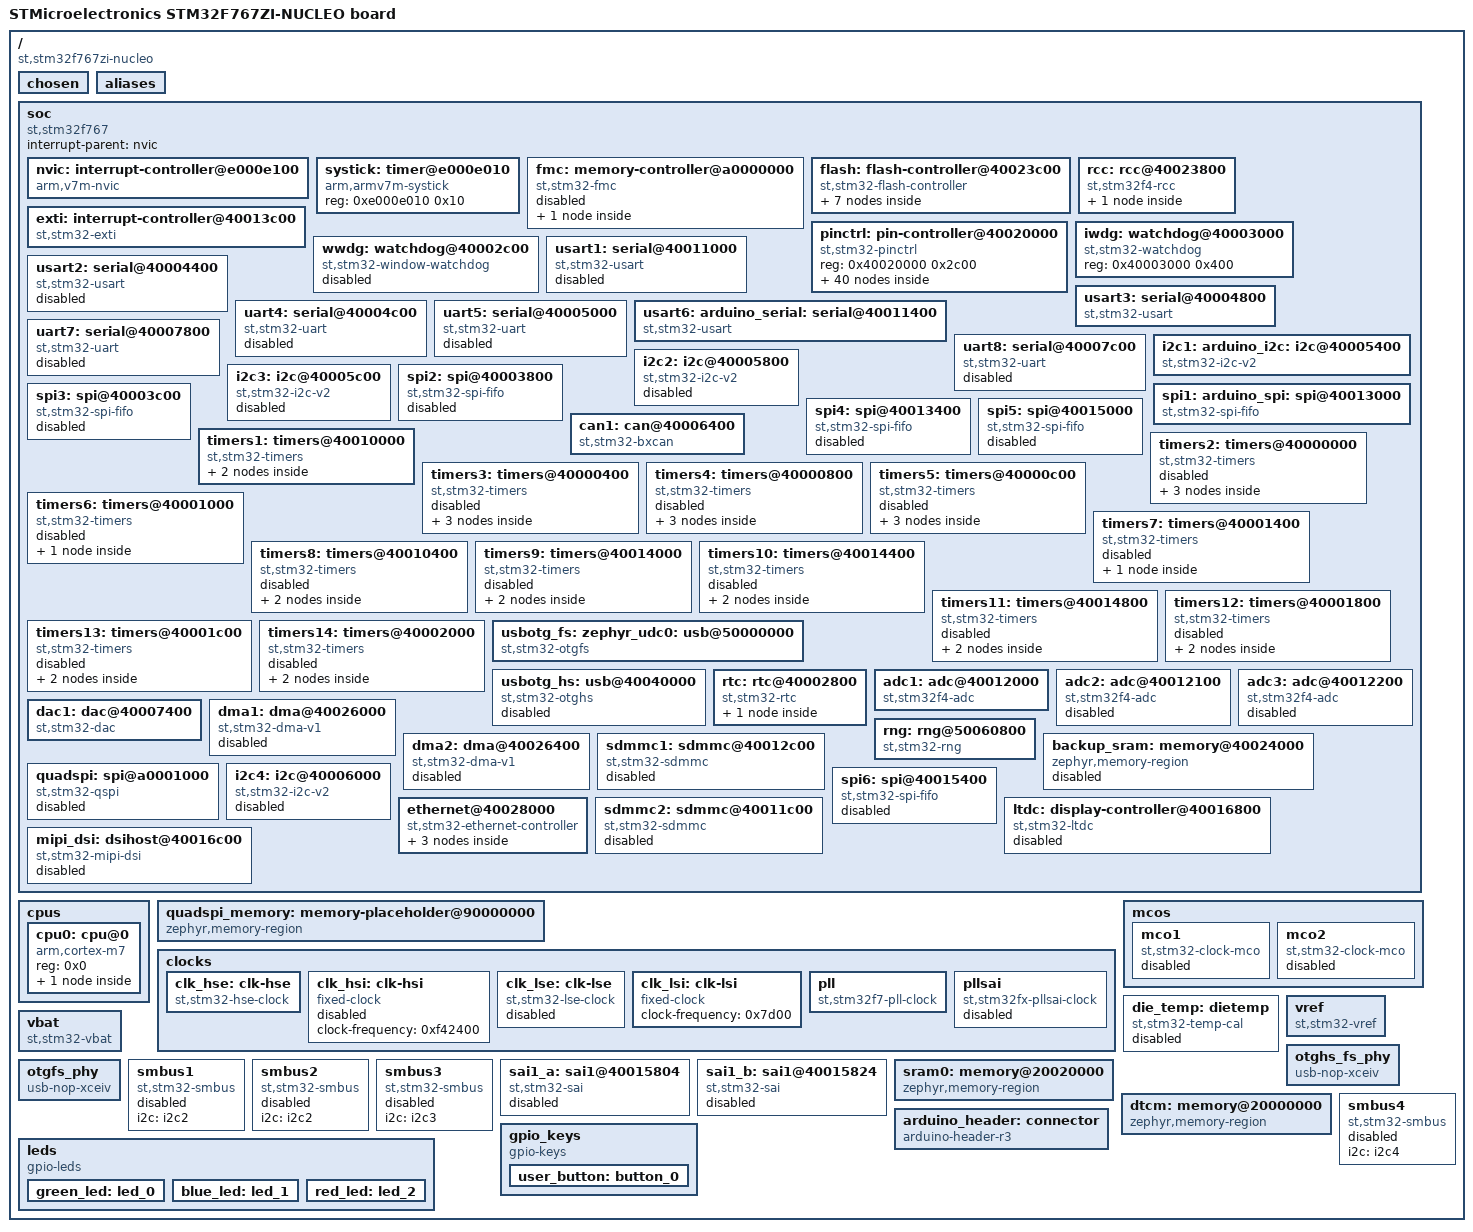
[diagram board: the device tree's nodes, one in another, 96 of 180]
/dts-v1/;

/* node '/' defined in zephyr/dts/common/skeleton.dtsi:9 */
/ {
	#address-cells = < 0x1 >;                              /* in zephyr/dts/common/skeleton.dtsi:10 */
	#size-cells = < 0x1 >;                                 /* in zephyr/dts/common/skeleton.dtsi:11 */
	model = "STMicroelectronics STM32F767ZI-NUCLEO board"; /* in zephyr/boards/st/nucleo_f767zi/nucleo_f767zi.dts:21 */
	compatible = "st,stm32f767zi-nucleo";                  /* in zephyr/boards/st/nucleo_f767zi/nucleo_f767zi.dts:22 */

	/* node '/chosen' defined in zephyr/dts/common/skeleton.dtsi:13 */
	chosen {
		zephyr,entropy = &rng;                    /* in zephyr/dts/arm/st/f7/stm32f7.dtsi:29 */
		zephyr,flash-controller = &flash;         /* in zephyr/dts/arm/st/f7/stm32f7.dtsi:30 */
		zephyr,console = &usart3;                 /* in zephyr/boards/st/nucleo_f767zi/nucleo_f767zi.dts:25 */
		zephyr,shell-uart = &usart3;              /* in zephyr/boards/st/nucleo_f767zi/nucleo_f767zi.dts:26 */
		zephyr,sram = &sram0;                     /* in zephyr/boards/st/nucleo_f767zi/nucleo_f767zi.dts:27 */
		zephyr,flash = &flash0;                   /* in zephyr/boards/st/nucleo_f767zi/nucleo_f767zi.dts:28 */
		zephyr,code-partition = &slot0_partition; /* in zephyr/boards/st/nucleo_f767zi/nucleo_f767zi.dts:29 */
		zephyr,dtcm = &dtcm;                      /* in zephyr/boards/st/nucleo_f767zi/nucleo_f767zi.dts:30 */
		zephyr,canbus = &can1;                    /* in zephyr/boards/st/nucleo_f767zi/nucleo_f767zi.dts:31 */
	};

	/* node '/aliases' defined in zephyr/dts/common/skeleton.dtsi:15 */
	aliases {
		led0 = &green_led;    /* in zephyr/boards/st/nucleo_f767zi/nucleo_f767zi.dts:64 */
		led1 = &blue_led;     /* in zephyr/boards/st/nucleo_f767zi/nucleo_f767zi.dts:65 */
		led2 = &red_led;      /* in zephyr/boards/st/nucleo_f767zi/nucleo_f767zi.dts:66 */
		sw0 = &user_button;   /* in zephyr/boards/st/nucleo_f767zi/nucleo_f767zi.dts:67 */
		watchdog0 = &iwdg;    /* in zephyr/boards/st/nucleo_f767zi/nucleo_f767zi.dts:68 */
		volt-sensor0 = &vref; /* in zephyr/boards/st/nucleo_f767zi/nucleo_f767zi.dts:69 */
		volt-sensor1 = &vbat; /* in zephyr/boards/st/nucleo_f767zi/nucleo_f767zi.dts:70 */
	};

	/* node '/soc' defined in zephyr/dts/arm/armv7-m.dtsi:6 */
	soc {
		#address-cells = < 0x1 >;     /* in zephyr/dts/arm/armv7-m.dtsi:7 */
		#size-cells = < 0x1 >;        /* in zephyr/dts/arm/armv7-m.dtsi:8 */
		interrupt-parent = < &nvic >; /* in zephyr/dts/arm/armv7-m.dtsi:10 */
		ranges;                       /* in zephyr/dts/arm/armv7-m.dtsi:11 */
		compatible = "st,stm32f767",
		             "st,stm32f7",
		             "simple-bus";    /* in zephyr/dts/arm/st/f7/stm32f767.dtsi:13 */

		/* node '/soc/interrupt-controller@e000e100' defined in zephyr/dts/arm/armv7-m.dtsi:13 */
		nvic: interrupt-controller@e000e100 {
			#address-cells = < 0x1 >;            /* in zephyr/dts/arm/armv7-m.dtsi:14 */
			compatible = "arm,v7m-nvic";         /* in zephyr/dts/arm/armv7-m.dtsi:15 */
			reg = < 0xe000e100 0xc00 >;          /* in zephyr/dts/arm/armv7-m.dtsi:16 */
			interrupt-controller;                /* in zephyr/dts/arm/armv7-m.dtsi:17 */
			#interrupt-cells = < 0x2 >;          /* in zephyr/dts/arm/armv7-m.dtsi:18 */
			arm,num-irq-priority-bits = < 0x4 >; /* in zephyr/dts/arm/st/f7/stm32f7.dtsi:1018 */
			phandle = < 0x1 >;                   /* in zephyr/dts/arm/armv7-m.dtsi:10 */
		};

		/* node '/soc/timer@e000e010' defined in zephyr/dts/arm/armv7-m.dtsi:21 */
		systick: timer@e000e010 {
			compatible = "arm,armv7m-systick"; /* in zephyr/dts/arm/armv7-m.dtsi:22 */
			reg = < 0xe000e010 0x10 >;         /* in zephyr/dts/arm/armv7-m.dtsi:23 */
		};

		/* node '/soc/memory-controller@a0000000' defined in zephyr/dts/arm/st/f7/stm32f7.dtsi:113 */
		fmc: memory-controller@a0000000 {
			compatible = "st,stm32-fmc"; /* in zephyr/dts/arm/st/f7/stm32f7.dtsi:114 */
			reg = < 0xa0000000 0x400 >;  /* in zephyr/dts/arm/st/f7/stm32f7.dtsi:115 */
			clocks = < &rcc 0x38 0x1 >;  /* in zephyr/dts/arm/st/f7/stm32f7.dtsi:116 */
			status = "disabled";         /* in zephyr/dts/arm/st/f7/stm32f7.dtsi:117 */

			/* node '/soc/memory-controller@a0000000/sdram' defined in zephyr/dts/arm/st/f7/stm32f7.dtsi:119 */
			sdram: sdram {
				compatible = "st,stm32-fmc-sdram"; /* in zephyr/dts/arm/st/f7/stm32f7.dtsi:120 */
				#address-cells = < 0x1 >;          /* in zephyr/dts/arm/st/f7/stm32f7.dtsi:121 */
				#size-cells = < 0x0 >;             /* in zephyr/dts/arm/st/f7/stm32f7.dtsi:122 */
				status = "disabled";               /* in zephyr/dts/arm/st/f7/stm32f7.dtsi:123 */
			};
		};

		/* node '/soc/flash-controller@40023c00' defined in zephyr/dts/arm/st/f7/stm32f7.dtsi:127 */
		flash: flash-controller@40023c00 {
			compatible = "st,stm32-flash-controller",
			             "st,stm32f7-flash-controller"; /* in zephyr/dts/arm/st/f7/stm32f7.dtsi:128 */
			reg = < 0x40023c00 0x400 >;                 /* in zephyr/dts/arm/st/f7/stm32f7.dtsi:129 */
			interrupts = < 0x4 0x0 >;                   /* in zephyr/dts/arm/st/f7/stm32f7.dtsi:130 */
			#address-cells = < 0x1 >;                   /* in zephyr/dts/arm/st/f7/stm32f7.dtsi:132 */
			#size-cells = < 0x1 >;                      /* in zephyr/dts/arm/st/f7/stm32f7.dtsi:133 */

			/* node '/soc/flash-controller@40023c00/flash@8000000' defined in zephyr/dts/arm/st/f7/stm32f7.dtsi:135 */
			flash0: flash@8000000 {
				compatible = "st,stm32-nv-flash",
				             "soc-nv-flash";      /* in zephyr/dts/arm/st/f7/stm32f7.dtsi:136 */
				write-block-size = < 0x1 >;       /* in zephyr/dts/arm/st/f7/stm32f7.dtsi:138 */
				max-erase-time = < 0xfa0 >;       /* in zephyr/dts/arm/st/f7/stm32f7.dtsi:140 */
				reg = < 0x8000000 0x200000 >;     /* in zephyr/dts/arm/st/f7/stm32f767Xi.dtsi:13 */

				/* node '/soc/flash-controller@40023c00/flash@8000000/partitions' defined in zephyr/boards/st/nucleo_f767zi/nucleo_f767zi.dts:219 */
				partitions {
					compatible = "fixed-partitions"; /* in zephyr/boards/st/nucleo_f767zi/nucleo_f767zi.dts:220 */
					#address-cells = < 0x1 >;        /* in zephyr/boards/st/nucleo_f767zi/nucleo_f767zi.dts:221 */
					#size-cells = < 0x1 >;           /* in zephyr/boards/st/nucleo_f767zi/nucleo_f767zi.dts:222 */

					/* node '/soc/flash-controller@40023c00/flash@8000000/partitions/partition@0' defined in zephyr/boards/st/nucleo_f767zi/nucleo_f767zi.dts:228 */
					boot_partition: partition@0 {
						label = "mcuboot";     /* in zephyr/boards/st/nucleo_f767zi/nucleo_f767zi.dts:229 */
						reg = < 0x0 0x10000 >; /* in zephyr/boards/st/nucleo_f767zi/nucleo_f767zi.dts:230 */
						read-only;             /* in zephyr/boards/st/nucleo_f767zi/nucleo_f767zi.dts:231 */
					};

					/* node '/soc/flash-controller@40023c00/flash@8000000/partitions/partition@10000' defined in zephyr/boards/st/nucleo_f767zi/nucleo_f767zi.dts:239 */
					storage_partition: partition@10000 {
						label = "storage";         /* in zephyr/boards/st/nucleo_f767zi/nucleo_f767zi.dts:240 */
						reg = < 0x10000 0x10000 >; /* in zephyr/boards/st/nucleo_f767zi/nucleo_f767zi.dts:241 */
					};

					/* node '/soc/flash-controller@40023c00/flash@8000000/partitions/partition@40000' defined in zephyr/boards/st/nucleo_f767zi/nucleo_f767zi.dts:251 */
					slot0_partition: partition@40000 {
						label = "image-0";         /* in zephyr/boards/st/nucleo_f767zi/nucleo_f767zi.dts:252 */
						reg = < 0x40000 0xc0000 >; /* in zephyr/boards/st/nucleo_f767zi/nucleo_f767zi.dts:253 */
					};

					/* node '/soc/flash-controller@40023c00/flash@8000000/partitions/partition@100000' defined in zephyr/boards/st/nucleo_f767zi/nucleo_f767zi.dts:259 */
					slot1_partition: partition@100000 {
						label = "image-1";          /* in zephyr/boards/st/nucleo_f767zi/nucleo_f767zi.dts:260 */
						reg = < 0x100000 0xc0000 >; /* in zephyr/boards/st/nucleo_f767zi/nucleo_f767zi.dts:261 */
					};

					/* node '/soc/flash-controller@40023c00/flash@8000000/partitions/partition@1C0000' defined in zephyr/boards/st/nucleo_f767zi/nucleo_f767zi.dts:267 */
					scratch_partition: partition@1C0000 {
						label = "image-scratch";    /* in zephyr/boards/st/nucleo_f767zi/nucleo_f767zi.dts:268 */
						reg = < 0x1c0000 0x40000 >; /* in zephyr/boards/st/nucleo_f767zi/nucleo_f767zi.dts:269 */
					};
				};
			};
		};

		/* node '/soc/rcc@40023800' defined in zephyr/dts/arm/st/f7/stm32f7.dtsi:144 */
		rcc: rcc@40023800 {
			compatible = "st,stm32f4-rcc";   /* in zephyr/dts/arm/st/f7/stm32f7.dtsi:145 */
			#clock-cells = < 0x2 >;          /* in zephyr/dts/arm/st/f7/stm32f7.dtsi:146 */
			reg = < 0x40023800 0x400 >;      /* in zephyr/dts/arm/st/f7/stm32f7.dtsi:147 */
			clocks = < &pll >;               /* in zephyr/boards/st/nucleo_f767zi/nucleo_f767zi.dts:94 */
			clock-frequency = < 0xcdfe600 >; /* in zephyr/boards/st/nucleo_f767zi/nucleo_f767zi.dts:95 */
			ahb-prescaler = < 0x1 >;         /* in zephyr/boards/st/nucleo_f767zi/nucleo_f767zi.dts:96 */
			apb1-prescaler = < 0x4 >;        /* in zephyr/boards/st/nucleo_f767zi/nucleo_f767zi.dts:97 */
			apb2-prescaler = < 0x2 >;        /* in zephyr/boards/st/nucleo_f767zi/nucleo_f767zi.dts:98 */
			phandle = < 0x2 >;               /* in zephyr/dts/arm/st/f7/stm32f7.dtsi:116 */

			/* node '/soc/rcc@40023800/reset-controller' defined in zephyr/dts/arm/st/f7/stm32f7.dtsi:149 */
			rctl: reset-controller {
				compatible = "st,stm32-rcc-rctl"; /* in zephyr/dts/arm/st/f7/stm32f7.dtsi:150 */
				#reset-cells = < 0x1 >;           /* in zephyr/dts/arm/st/f7/stm32f7.dtsi:151 */
				phandle = < 0x4 >;                /* in zephyr/dts/arm/st/f7/stm32f7.dtsi:268 */
			};
		};

		/* node '/soc/interrupt-controller@40013c00' defined in zephyr/dts/arm/st/f7/stm32f7.dtsi:155 */
		exti: interrupt-controller@40013c00 {
			compatible = "st,stm32-exti";  /* in zephyr/dts/arm/st/f7/stm32f7.dtsi:156 */
			interrupt-controller;          /* in zephyr/dts/arm/st/f7/stm32f7.dtsi:157 */
			#interrupt-cells = < 0x1 >;    /* in zephyr/dts/arm/st/f7/stm32f7.dtsi:158 */
			#address-cells = < 0x0 >;      /* in zephyr/dts/arm/st/f7/stm32f7.dtsi:159 */
			reg = < 0x40013c00 0x400 >;    /* in zephyr/dts/arm/st/f7/stm32f7.dtsi:160 */
			clocks = < &rcc 0x44 0x4000 >; /* in zephyr/dts/arm/st/f7/stm32f7.dtsi:161 */
			num-lines = < 0x20 >;          /* in zephyr/dts/arm/st/f7/stm32f7.dtsi:162 */
			interrupts = < 0x6 0x0 >,
			             < 0x7 0x0 >,
			             < 0x8 0x0 >,
			             < 0x9 0x0 >,
			             < 0xa 0x0 >,
			             < 0x17 0x0 >,
			             < 0x28 0x0 >;     /* in zephyr/dts/arm/st/f7/stm32f7.dtsi:163 */
			interrupt-names = "line0",
			                  "line1",
			                  "line2",
			                  "line3",
			                  "line4",
			                  "line5-9",
			                  "line10-15"; /* in zephyr/dts/arm/st/f7/stm32f7.dtsi:165 */
			line-ranges = < 0x0 0x1 >,
			              < 0x1 0x1 >,
			              < 0x2 0x1 >,
			              < 0x3 0x1 >,
			              < 0x4 0x1 >,
			              < 0x5 0x5 >,
			              < 0xa 0x6 >;     /* in zephyr/dts/arm/st/f7/stm32f7.dtsi:167 */
		};

		/* node '/soc/pin-controller@40020000' defined in zephyr/dts/arm/st/f7/stm32f7.dtsi:171 */
		pinctrl: pin-controller@40020000 {
			compatible = "st,stm32-pinctrl"; /* in zephyr/dts/arm/st/f7/stm32f7.dtsi:172 */
			#address-cells = < 0x1 >;        /* in zephyr/dts/arm/st/f7/stm32f7.dtsi:173 */
			#size-cells = < 0x1 >;           /* in zephyr/dts/arm/st/f7/stm32f7.dtsi:174 */
			reg = < 0x40020000 0x2c00 >;     /* in zephyr/dts/arm/st/f7/stm32f765.dtsi:30 */

			/* node '/soc/pin-controller@40020000/gpio@40020000' defined in zephyr/dts/arm/st/f7/stm32f7.dtsi:177 */
			gpioa: gpio@40020000 {
				compatible = "st,stm32-gpio"; /* in zephyr/dts/arm/st/f7/stm32f7.dtsi:178 */
				gpio-controller;              /* in zephyr/dts/arm/st/f7/stm32f7.dtsi:179 */
				#gpio-cells = < 0x2 >;        /* in zephyr/dts/arm/st/f7/stm32f7.dtsi:180 */
				reg = < 0x40020000 0x400 >;   /* in zephyr/dts/arm/st/f7/stm32f7.dtsi:181 */
				clocks = < &rcc 0x30 0x1 >;   /* in zephyr/dts/arm/st/f7/stm32f7.dtsi:182 */
				phandle = < 0x2c >;           /* in zephyr/boards/st/nucleo_f767zi/arduino_r3_connector.dtsi:15 */
			};

			/* node '/soc/pin-controller@40020000/gpio@40020400' defined in zephyr/dts/arm/st/f7/stm32f7.dtsi:185 */
			gpiob: gpio@40020400 {
				compatible = "st,stm32-gpio"; /* in zephyr/dts/arm/st/f7/stm32f7.dtsi:186 */
				gpio-controller;              /* in zephyr/dts/arm/st/f7/stm32f7.dtsi:187 */
				#gpio-cells = < 0x2 >;        /* in zephyr/dts/arm/st/f7/stm32f7.dtsi:188 */
				reg = < 0x40020400 0x400 >;   /* in zephyr/dts/arm/st/f7/stm32f7.dtsi:189 */
				clocks = < &rcc 0x30 0x2 >;   /* in zephyr/dts/arm/st/f7/stm32f7.dtsi:190 */
				phandle = < 0x31 >;           /* in zephyr/boards/st/nucleo_f767zi/arduino_r3_connector.dtsi:15 */
			};

			/* node '/soc/pin-controller@40020000/gpio@40020800' defined in zephyr/dts/arm/st/f7/stm32f7.dtsi:193 */
			gpioc: gpio@40020800 {
				compatible = "st,stm32-gpio"; /* in zephyr/dts/arm/st/f7/stm32f7.dtsi:194 */
				gpio-controller;              /* in zephyr/dts/arm/st/f7/stm32f7.dtsi:195 */
				#gpio-cells = < 0x2 >;        /* in zephyr/dts/arm/st/f7/stm32f7.dtsi:196 */
				reg = < 0x40020800 0x400 >;   /* in zephyr/dts/arm/st/f7/stm32f7.dtsi:197 */
				clocks = < &rcc 0x30 0x4 >;   /* in zephyr/dts/arm/st/f7/stm32f7.dtsi:198 */
				phandle = < 0x2d >;           /* in zephyr/boards/st/nucleo_f767zi/arduino_r3_connector.dtsi:15 */
			};

			/* node '/soc/pin-controller@40020000/gpio@40020C00' defined in zephyr/dts/arm/st/f7/stm32f7.dtsi:201 */
			gpiod: gpio@40020C00 {
				compatible = "st,stm32-gpio"; /* in zephyr/dts/arm/st/f7/stm32f7.dtsi:202 */
				gpio-controller;              /* in zephyr/dts/arm/st/f7/stm32f7.dtsi:203 */
				#gpio-cells = < 0x2 >;        /* in zephyr/dts/arm/st/f7/stm32f7.dtsi:204 */
				reg = < 0x40020c00 0x400 >;   /* in zephyr/dts/arm/st/f7/stm32f7.dtsi:205 */
				clocks = < &rcc 0x30 0x8 >;   /* in zephyr/dts/arm/st/f7/stm32f7.dtsi:206 */
				phandle = < 0x12 >;           /* in zephyr/boards/st/nucleo_f767zi/nucleo_f767zi.dts:151 */
			};

			/* node '/soc/pin-controller@40020000/gpio@40021000' defined in zephyr/dts/arm/st/f7/stm32f7.dtsi:209 */
			gpioe: gpio@40021000 {
				compatible = "st,stm32-gpio"; /* in zephyr/dts/arm/st/f7/stm32f7.dtsi:210 */
				gpio-controller;              /* in zephyr/dts/arm/st/f7/stm32f7.dtsi:211 */
				#gpio-cells = < 0x2 >;        /* in zephyr/dts/arm/st/f7/stm32f7.dtsi:212 */
				reg = < 0x40021000 0x400 >;   /* in zephyr/dts/arm/st/f7/stm32f7.dtsi:213 */
				clocks = < &rcc 0x30 0x10 >;  /* in zephyr/dts/arm/st/f7/stm32f7.dtsi:214 */
				phandle = < 0x30 >;           /* in zephyr/boards/st/nucleo_f767zi/arduino_r3_connector.dtsi:15 */
			};

			/* node '/soc/pin-controller@40020000/gpio@40021400' defined in zephyr/dts/arm/st/f7/stm32f7.dtsi:217 */
			gpiof: gpio@40021400 {
				compatible = "st,stm32-gpio"; /* in zephyr/dts/arm/st/f7/stm32f7.dtsi:218 */
				gpio-controller;              /* in zephyr/dts/arm/st/f7/stm32f7.dtsi:219 */
				#gpio-cells = < 0x2 >;        /* in zephyr/dts/arm/st/f7/stm32f7.dtsi:220 */
				reg = < 0x40021400 0x400 >;   /* in zephyr/dts/arm/st/f7/stm32f7.dtsi:221 */
				clocks = < &rcc 0x30 0x20 >;  /* in zephyr/dts/arm/st/f7/stm32f7.dtsi:222 */
				phandle = < 0x2e >;           /* in zephyr/boards/st/nucleo_f767zi/arduino_r3_connector.dtsi:15 */
			};

			/* node '/soc/pin-controller@40020000/gpio@40021800' defined in zephyr/dts/arm/st/f7/stm32f7.dtsi:225 */
			gpiog: gpio@40021800 {
				compatible = "st,stm32-gpio"; /* in zephyr/dts/arm/st/f7/stm32f7.dtsi:226 */
				gpio-controller;              /* in zephyr/dts/arm/st/f7/stm32f7.dtsi:227 */
				#gpio-cells = < 0x2 >;        /* in zephyr/dts/arm/st/f7/stm32f7.dtsi:228 */
				reg = < 0x40021800 0x400 >;   /* in zephyr/dts/arm/st/f7/stm32f7.dtsi:229 */
				clocks = < &rcc 0x30 0x40 >;  /* in zephyr/dts/arm/st/f7/stm32f7.dtsi:230 */
				phandle = < 0x2f >;           /* in zephyr/boards/st/nucleo_f767zi/arduino_r3_connector.dtsi:15 */
			};

			/* node '/soc/pin-controller@40020000/gpio@40021C00' defined in zephyr/dts/arm/st/f7/stm32f7.dtsi:233 */
			gpioh: gpio@40021C00 {
				compatible = "st,stm32-gpio"; /* in zephyr/dts/arm/st/f7/stm32f7.dtsi:234 */
				gpio-controller;              /* in zephyr/dts/arm/st/f7/stm32f7.dtsi:235 */
				#gpio-cells = < 0x2 >;        /* in zephyr/dts/arm/st/f7/stm32f7.dtsi:236 */
				reg = < 0x40021c00 0x400 >;   /* in zephyr/dts/arm/st/f7/stm32f7.dtsi:237 */
				clocks = < &rcc 0x30 0x80 >;  /* in zephyr/dts/arm/st/f7/stm32f7.dtsi:238 */
			};

			/* node '/soc/pin-controller@40020000/gpio@40022000' defined in zephyr/dts/arm/st/f7/stm32f7.dtsi:241 */
			gpioi: gpio@40022000 {
				compatible = "st,stm32-gpio"; /* in zephyr/dts/arm/st/f7/stm32f7.dtsi:242 */
				gpio-controller;              /* in zephyr/dts/arm/st/f7/stm32f7.dtsi:243 */
				#gpio-cells = < 0x2 >;        /* in zephyr/dts/arm/st/f7/stm32f7.dtsi:244 */
				reg = < 0x40022000 0x400 >;   /* in zephyr/dts/arm/st/f7/stm32f7.dtsi:245 */
				clocks = < &rcc 0x30 0x100 >; /* in zephyr/dts/arm/st/f7/stm32f7.dtsi:246 */
			};

			/* node '/soc/pin-controller@40020000/gpio@40022400' defined in zephyr/dts/arm/st/f7/stm32f765.dtsi:32 */
			gpioj: gpio@40022400 {
				compatible = "st,stm32-gpio"; /* in zephyr/dts/arm/st/f7/stm32f765.dtsi:33 */
				gpio-controller;              /* in zephyr/dts/arm/st/f7/stm32f765.dtsi:34 */
				#gpio-cells = < 0x2 >;        /* in zephyr/dts/arm/st/f7/stm32f765.dtsi:35 */
				reg = < 0x40022400 0x400 >;   /* in zephyr/dts/arm/st/f7/stm32f765.dtsi:36 */
				clocks = < &rcc 0x30 0x200 >; /* in zephyr/dts/arm/st/f7/stm32f765.dtsi:37 */
			};

			/* node '/soc/pin-controller@40020000/gpio@40022800' defined in zephyr/dts/arm/st/f7/stm32f765.dtsi:40 */
			gpiok: gpio@40022800 {
				compatible = "st,stm32-gpio"; /* in zephyr/dts/arm/st/f7/stm32f765.dtsi:41 */
				gpio-controller;              /* in zephyr/dts/arm/st/f7/stm32f765.dtsi:42 */
				#gpio-cells = < 0x2 >;        /* in zephyr/dts/arm/st/f7/stm32f765.dtsi:43 */
				reg = < 0x40022800 0x400 >;   /* in zephyr/dts/arm/st/f7/stm32f765.dtsi:44 */
				clocks = < &rcc 0x30 0x400 >; /* in zephyr/dts/arm/st/f7/stm32f765.dtsi:45 */
			};

			/* node '/soc/pin-controller@40020000/adc1_in0_pa0' defined in modules/hal/stm32/dts/st/f7/stm32f767zitx-pinctrl.dtsi:15 */
			adc1_in0_pa0: adc1_in0_pa0 {
				pinmux = < 0x10 >;  /* in modules/hal/stm32/dts/st/f7/stm32f767zitx-pinctrl.dtsi:16 */
				phandle = < 0x1a >; /* in zephyr/boards/st/nucleo_f767zi/nucleo_f767zi.dts:176 */
			};

			/* node '/soc/pin-controller@40020000/can1_rx_pd0' defined in modules/hal/stm32/dts/st/f7/stm32f767zitx-pinctrl.dtsi:677 */
			can1_rx_pd0: can1_rx_pd0 {
				pinmux = < 0x609 >; /* in modules/hal/stm32/dts/st/f7/stm32f767zitx-pinctrl.dtsi:678 */
				bias-pull-up;       /* in modules/hal/stm32/dts/st/f7/stm32f767zitx-pinctrl.dtsi:679 */
				phandle = < 0x13 >; /* in zephyr/boards/st/nucleo_f767zi/nucleo_f767zi.dts:170 */
			};

			/* node '/soc/pin-controller@40020000/can1_tx_pd1' defined in modules/hal/stm32/dts/st/f7/stm32f767zitx-pinctrl.dtsi:712 */
			can1_tx_pd1: can1_tx_pd1 {
				pinmux = < 0x629 >; /* in modules/hal/stm32/dts/st/f7/stm32f767zitx-pinctrl.dtsi:713 */
				phandle = < 0x14 >; /* in zephyr/boards/st/nucleo_f767zi/nucleo_f767zi.dts:170 */
			};

			/* node '/soc/pin-controller@40020000/dac_out1_pa4' defined in modules/hal/stm32/dts/st/f7/stm32f767zitx-pinctrl.dtsi:734 */
			dac_out1_pa4: dac_out1_pa4 {
				pinmux = < 0x90 >;  /* in modules/hal/stm32/dts/st/f7/stm32f767zitx-pinctrl.dtsi:735 */
				phandle = < 0x1b >; /* in zephyr/boards/st/nucleo_f767zi/nucleo_f767zi.dts:185 */
			};

			/* node '/soc/pin-controller@40020000/eth_ref_clk_pa1' defined in modules/hal/stm32/dts/st/f7/stm32f767zitx-pinctrl.dtsi:1168 */
			eth_ref_clk_pa1: eth_ref_clk_pa1 {
				pinmux = < 0x2b >;             /* in modules/hal/stm32/dts/st/f7/stm32f767zitx-pinctrl.dtsi:1169 */
				slew-rate = "very-high-speed"; /* in modules/hal/stm32/dts/st/f7/stm32f767zitx-pinctrl.dtsi:1170 */
				phandle = < 0x1e >;            /* in zephyr/boards/st/nucleo_f767zi/nucleo_f767zi.dts:195 */
			};

			/* node '/soc/pin-controller@40020000/eth_mdio_pa2' defined in modules/hal/stm32/dts/st/f7/stm32f767zitx-pinctrl.dtsi:1178 */
			eth_mdio_pa2: eth_mdio_pa2 {
				pinmux = < 0x4b >;             /* in modules/hal/stm32/dts/st/f7/stm32f767zitx-pinctrl.dtsi:1179 */
				slew-rate = "very-high-speed"; /* in modules/hal/stm32/dts/st/f7/stm32f767zitx-pinctrl.dtsi:1180 */
				phandle = < 0x24 >;            /* in zephyr/boards/st/nucleo_f767zi/nucleo_f767zi.dts:209 */
			};

			/* node '/soc/pin-controller@40020000/eth_crs_dv_pa7' defined in modules/hal/stm32/dts/st/f7/stm32f767zitx-pinctrl.dtsi:1188 */
			eth_crs_dv_pa7: eth_crs_dv_pa7 {
				pinmux = < 0xeb >;             /* in modules/hal/stm32/dts/st/f7/stm32f767zitx-pinctrl.dtsi:1189 */
				slew-rate = "very-high-speed"; /* in modules/hal/stm32/dts/st/f7/stm32f767zitx-pinctrl.dtsi:1190 */
				phandle = < 0x1f >;            /* in zephyr/boards/st/nucleo_f767zi/nucleo_f767zi.dts:195 */
			};

			/* node '/soc/pin-controller@40020000/eth_txd1_pb13' defined in modules/hal/stm32/dts/st/f7/stm32f767zitx-pinctrl.dtsi:1233 */
			eth_txd1_pb13: eth_txd1_pb13 {
				pinmux = < 0x3ab >;            /* in modules/hal/stm32/dts/st/f7/stm32f767zitx-pinctrl.dtsi:1234 */
				slew-rate = "very-high-speed"; /* in modules/hal/stm32/dts/st/f7/stm32f767zitx-pinctrl.dtsi:1235 */
				phandle = < 0x22 >;            /* in zephyr/boards/st/nucleo_f767zi/nucleo_f767zi.dts:195 */
			};

			/* node '/soc/pin-controller@40020000/eth_mdc_pc1' defined in modules/hal/stm32/dts/st/f7/stm32f767zitx-pinctrl.dtsi:1238 */
			eth_mdc_pc1: eth_mdc_pc1 {
				pinmux = < 0x42b >;            /* in modules/hal/stm32/dts/st/f7/stm32f767zitx-pinctrl.dtsi:1239 */
				slew-rate = "very-high-speed"; /* in modules/hal/stm32/dts/st/f7/stm32f767zitx-pinctrl.dtsi:1240 */
				phandle = < 0x25 >;            /* in zephyr/boards/st/nucleo_f767zi/nucleo_f767zi.dts:209 */
			};

			/* node '/soc/pin-controller@40020000/eth_rxd0_pc4' defined in modules/hal/stm32/dts/st/f7/stm32f767zitx-pinctrl.dtsi:1253 */
			eth_rxd0_pc4: eth_rxd0_pc4 {
				pinmux = < 0x48b >;            /* in modules/hal/stm32/dts/st/f7/stm32f767zitx-pinctrl.dtsi:1254 */
				slew-rate = "very-high-speed"; /* in modules/hal/stm32/dts/st/f7/stm32f767zitx-pinctrl.dtsi:1255 */
				phandle = < 0x1c >;            /* in zephyr/boards/st/nucleo_f767zi/nucleo_f767zi.dts:195 */
			};

			/* node '/soc/pin-controller@40020000/eth_rxd1_pc5' defined in modules/hal/stm32/dts/st/f7/stm32f767zitx-pinctrl.dtsi:1258 */
			eth_rxd1_pc5: eth_rxd1_pc5 {
				pinmux = < 0x4ab >;            /* in modules/hal/stm32/dts/st/f7/stm32f767zitx-pinctrl.dtsi:1259 */
				slew-rate = "very-high-speed"; /* in modules/hal/stm32/dts/st/f7/stm32f767zitx-pinctrl.dtsi:1260 */
				phandle = < 0x1d >;            /* in zephyr/boards/st/nucleo_f767zi/nucleo_f767zi.dts:195 */
			};

			/* node '/soc/pin-controller@40020000/eth_tx_en_pg11' defined in modules/hal/stm32/dts/st/f7/stm32f767zitx-pinctrl.dtsi:1273 */
			eth_tx_en_pg11: eth_tx_en_pg11 {
				pinmux = < 0xd6b >;            /* in modules/hal/stm32/dts/st/f7/stm32f767zitx-pinctrl.dtsi:1274 */
				slew-rate = "very-high-speed"; /* in modules/hal/stm32/dts/st/f7/stm32f767zitx-pinctrl.dtsi:1275 */
				phandle = < 0x20 >;            /* in zephyr/boards/st/nucleo_f767zi/nucleo_f767zi.dts:195 */
			};

			/* node '/soc/pin-controller@40020000/eth_txd0_pg13' defined in modules/hal/stm32/dts/st/f7/stm32f767zitx-pinctrl.dtsi:1278 */
			eth_txd0_pg13: eth_txd0_pg13 {
				pinmux = < 0xdab >;            /* in modules/hal/stm32/dts/st/f7/stm32f767zitx-pinctrl.dtsi:1279 */
				slew-rate = "very-high-speed"; /* in modules/hal/stm32/dts/st/f7/stm32f767zitx-pinctrl.dtsi:1280 */
				phandle = < 0x21 >;            /* in zephyr/boards/st/nucleo_f767zi/nucleo_f767zi.dts:195 */
			};

			/* node '/soc/pin-controller@40020000/i2c1_scl_pb8' defined in modules/hal/stm32/dts/st/f7/stm32f767zitx-pinctrl.dtsi:1736 */
			i2c1_scl_pb8: i2c1_scl_pb8 {
				pinmux = < 0x304 >; /* in modules/hal/stm32/dts/st/f7/stm32f767zitx-pinctrl.dtsi:1737 */
				bias-pull-up;       /* in modules/hal/stm32/dts/st/f7/stm32f767zitx-pinctrl.dtsi:1738 */
				drive-open-drain;   /* in modules/hal/stm32/dts/st/f7/stm32f767zitx-pinctrl.dtsi:1739 */
				phandle = < 0xd >;  /* in zephyr/boards/st/nucleo_f767zi/nucleo_f767zi.dts:131 */
			};

			/* node '/soc/pin-controller@40020000/i2c1_sda_pb9' defined in modules/hal/stm32/dts/st/f7/stm32f767zitx-pinctrl.dtsi:1792 */
			i2c1_sda_pb9: i2c1_sda_pb9 {
				pinmux = < 0x324 >; /* in modules/hal/stm32/dts/st/f7/stm32f767zitx-pinctrl.dtsi:1793 */
				bias-pull-up;       /* in modules/hal/stm32/dts/st/f7/stm32f767zitx-pinctrl.dtsi:1794 */
				drive-open-drain;   /* in modules/hal/stm32/dts/st/f7/stm32f767zitx-pinctrl.dtsi:1795 */
				phandle = < 0xe >;  /* in zephyr/boards/st/nucleo_f767zi/nucleo_f767zi.dts:131 */
			};

			/* node '/soc/pin-controller@40020000/spi1_miso_pa6' defined in modules/hal/stm32/dts/st/f7/stm32f767zitx-pinctrl.dtsi:2648 */
			spi1_miso_pa6: spi1_miso_pa6 {
				pinmux = < 0xc5 >;  /* in modules/hal/stm32/dts/st/f7/stm32f767zitx-pinctrl.dtsi:2649 */
				bias-pull-down;     /* in modules/hal/stm32/dts/st/f7/stm32f767zitx-pinctrl.dtsi:2650 */
				phandle = < 0x10 >; /* in zephyr/boards/st/nucleo_f767zi/nucleo_f767zi.dts:149 */
			};

			/* node '/soc/pin-controller@40020000/spi1_mosi_pa7' defined in modules/hal/stm32/dts/st/f7/stm32f767zitx-pinctrl.dtsi:2715 */
			spi1_mosi_pa7: spi1_mosi_pa7 {
				pinmux = < 0xe5 >;  /* in modules/hal/stm32/dts/st/f7/stm32f767zitx-pinctrl.dtsi:2716 */
				bias-pull-down;     /* in modules/hal/stm32/dts/st/f7/stm32f767zitx-pinctrl.dtsi:2717 */
				phandle = < 0x11 >; /* in zephyr/boards/st/nucleo_f767zi/nucleo_f767zi.dts:149 */
			};

			/* node '/soc/pin-controller@40020000/spi1_sck_pa5' defined in modules/hal/stm32/dts/st/f7/stm32f767zitx-pinctrl.dtsi:2879 */
			spi1_sck_pa5: spi1_sck_pa5 {
				pinmux = < 0xa5 >;             /* in modules/hal/stm32/dts/st/f7/stm32f767zitx-pinctrl.dtsi:2880 */
				bias-pull-down;                /* in modules/hal/stm32/dts/st/f7/stm32f767zitx-pinctrl.dtsi:2881 */
				slew-rate = "very-high-speed"; /* in modules/hal/stm32/dts/st/f7/stm32f767zitx-pinctrl.dtsi:2882 */
				phandle = < 0xf >;             /* in zephyr/boards/st/nucleo_f767zi/nucleo_f767zi.dts:149 */
			};

			/* node '/soc/pin-controller@40020000/tim1_ch3_pe13' defined in modules/hal/stm32/dts/st/f7/stm32f767zitx-pinctrl.dtsi:3075 */
			tim1_ch3_pe13: tim1_ch3_pe13 {
				pinmux = < 0x9a1 >; /* in modules/hal/stm32/dts/st/f7/stm32f767zitx-pinctrl.dtsi:3076 */
				phandle = < 0x15 >; /* in zephyr/boards/st/nucleo_f767zi/nucleo_f767zi.dts:143 */
			};

			/* node '/soc/pin-controller@40020000/usart2_cts_pd3' defined in modules/hal/stm32/dts/st/f7/stm32f767zitx-pinctrl.dtsi:3303 */
			usart2_cts_pd3: usart2_cts_pd3 {
				pinmux = < 0x667 >; /* in modules/hal/stm32/dts/st/f7/stm32f767zitx-pinctrl.dtsi:3304 */
				bias-pull-up;       /* in modules/hal/stm32/dts/st/f7/stm32f767zitx-pinctrl.dtsi:3305 */
				phandle = < 0x8 >;  /* in zephyr/boards/st/nucleo_f767zi/nucleo_f767zi.dts:102 */
			};

			/* node '/soc/pin-controller@40020000/usart2_rts_pd4' defined in modules/hal/stm32/dts/st/f7/stm32f767zitx-pinctrl.dtsi:3437 */
			usart2_rts_pd4: usart2_rts_pd4 {
				pinmux = < 0x687 >; /* in modules/hal/stm32/dts/st/f7/stm32f767zitx-pinctrl.dtsi:3438 */
				drive-push-pull;    /* in modules/hal/stm32/dts/st/f7/stm32f767zitx-pinctrl.dtsi:3439 */
				phandle = < 0x7 >;  /* in zephyr/boards/st/nucleo_f767zi/nucleo_f767zi.dts:102 */
			};

			/* node '/soc/pin-controller@40020000/usart2_rx_pd6' defined in modules/hal/stm32/dts/st/f7/stm32f767zitx-pinctrl.dtsi:3510 */
			usart2_rx_pd6: usart2_rx_pd6 {
				pinmux = < 0x6c7 >; /* in modules/hal/stm32/dts/st/f7/stm32f767zitx-pinctrl.dtsi:3511 */
				phandle = < 0x6 >;  /* in zephyr/boards/st/nucleo_f767zi/nucleo_f767zi.dts:102 */
			};

			/* node '/soc/pin-controller@40020000/usart3_rx_pd9' defined in modules/hal/stm32/dts/st/f7/stm32f767zitx-pinctrl.dtsi:3522 */
			usart3_rx_pd9: usart3_rx_pd9 {
				pinmux = < 0x727 >; /* in modules/hal/stm32/dts/st/f7/stm32f767zitx-pinctrl.dtsi:3523 */
				phandle = < 0xa >;  /* in zephyr/boards/st/nucleo_f767zi/nucleo_f767zi.dts:111 */
			};

			/* node '/soc/pin-controller@40020000/usart6_rx_pg9' defined in modules/hal/stm32/dts/st/f7/stm32f767zitx-pinctrl.dtsi:3562 */
			usart6_rx_pg9: usart6_rx_pg9 {
				pinmux = < 0xd28 >; /* in modules/hal/stm32/dts/st/f7/stm32f767zitx-pinctrl.dtsi:3563 */
				phandle = < 0xc >;  /* in zephyr/boards/st/nucleo_f767zi/nucleo_f767zi.dts:118 */
			};

			/* node '/soc/pin-controller@40020000/usart2_tx_pd5' defined in modules/hal/stm32/dts/st/f7/stm32f767zitx-pinctrl.dtsi:3608 */
			usart2_tx_pd5: usart2_tx_pd5 {
				pinmux = < 0x6a7 >; /* in modules/hal/stm32/dts/st/f7/stm32f767zitx-pinctrl.dtsi:3609 */
				bias-pull-up;       /* in modules/hal/stm32/dts/st/f7/stm32f767zitx-pinctrl.dtsi:3610 */
				phandle = < 0x5 >;  /* in zephyr/boards/st/nucleo_f767zi/nucleo_f767zi.dts:102 */
			};

			/* node '/soc/pin-controller@40020000/usart3_tx_pd8' defined in modules/hal/stm32/dts/st/f7/stm32f767zitx-pinctrl.dtsi:3623 */
			usart3_tx_pd8: usart3_tx_pd8 {
				pinmux = < 0x707 >; /* in modules/hal/stm32/dts/st/f7/stm32f767zitx-pinctrl.dtsi:3624 */
				bias-pull-up;       /* in modules/hal/stm32/dts/st/f7/stm32f767zitx-pinctrl.dtsi:3625 */
				phandle = < 0x9 >;  /* in zephyr/boards/st/nucleo_f767zi/nucleo_f767zi.dts:111 */
			};

			/* node '/soc/pin-controller@40020000/usart6_tx_pg14' defined in modules/hal/stm32/dts/st/f7/stm32f767zitx-pinctrl.dtsi:3673 */
			usart6_tx_pg14: usart6_tx_pg14 {
				pinmux = < 0xdc8 >; /* in modules/hal/stm32/dts/st/f7/stm32f767zitx-pinctrl.dtsi:3674 */
				bias-pull-up;       /* in modules/hal/stm32/dts/st/f7/stm32f767zitx-pinctrl.dtsi:3675 */
				phandle = < 0xb >;  /* in zephyr/boards/st/nucleo_f767zi/nucleo_f767zi.dts:118 */
			};

			/* node '/soc/pin-controller@40020000/usb_otg_fs_dm_pa11' defined in modules/hal/stm32/dts/st/f7/stm32f767zitx-pinctrl.dtsi:3717 */
			usb_otg_fs_dm_pa11: usb_otg_fs_dm_pa11 {
				pinmux = < 0x16a >; /* in modules/hal/stm32/dts/st/f7/stm32f767zitx-pinctrl.dtsi:3718 */
				phandle = < 0x17 >; /* in zephyr/boards/st/nucleo_f767zi/nucleo_f767zi.dts:125 */
			};

			/* node '/soc/pin-controller@40020000/usb_otg_fs_dp_pa12' defined in modules/hal/stm32/dts/st/f7/stm32f767zitx-pinctrl.dtsi:3721 */
			usb_otg_fs_dp_pa12: usb_otg_fs_dp_pa12 {
				pinmux = < 0x18a >; /* in modules/hal/stm32/dts/st/f7/stm32f767zitx-pinctrl.dtsi:3722 */
				phandle = < 0x18 >; /* in zephyr/boards/st/nucleo_f767zi/nucleo_f767zi.dts:125 */
			};
		};

		/* node '/soc/watchdog@40003000' defined in zephyr/dts/arm/st/f7/stm32f7.dtsi:250 */
		iwdg: watchdog@40003000 {
			compatible = "st,stm32-watchdog"; /* in zephyr/dts/arm/st/f7/stm32f7.dtsi:251 */
			reg = < 0x40003000 0x400 >;       /* in zephyr/dts/arm/st/f7/stm32f7.dtsi:252 */
			status = "okay";                  /* in zephyr/boards/st/nucleo_f767zi/nucleo_f767zi.dts:160 */
		};

		/* node '/soc/watchdog@40002c00' defined in zephyr/dts/arm/st/f7/stm32f7.dtsi:256 */
		wwdg: watchdog@40002c00 {
			compatible = "st,stm32-window-watchdog"; /* in zephyr/dts/arm/st/f7/stm32f7.dtsi:257 */
			reg = < 0x40002c00 0x400 >;              /* in zephyr/dts/arm/st/f7/stm32f7.dtsi:258 */
			clocks = < &rcc 0x40 0x800 >;            /* in zephyr/dts/arm/st/f7/stm32f7.dtsi:259 */
			interrupts = < 0x0 0x7 >;                /* in zephyr/dts/arm/st/f7/stm32f7.dtsi:260 */
			status = "disabled";                     /* in zephyr/dts/arm/st/f7/stm32f7.dtsi:261 */
		};

		/* node '/soc/serial@40011000' defined in zephyr/dts/arm/st/f7/stm32f7.dtsi:264 */
		usart1: serial@40011000 {
			compatible = "st,stm32-usart",
			             "st,stm32-uart";  /* in zephyr/dts/arm/st/f7/stm32f7.dtsi:265 */
			reg = < 0x40011000 0x400 >;    /* in zephyr/dts/arm/st/f7/stm32f7.dtsi:266 */
			clocks = < &rcc 0x44 0x10 >;   /* in zephyr/dts/arm/st/f7/stm32f7.dtsi:267 */
			resets = < &rctl 0x484 >;      /* in zephyr/dts/arm/st/f7/stm32f7.dtsi:268 */
			interrupts = < 0x25 0x0 >;     /* in zephyr/dts/arm/st/f7/stm32f7.dtsi:269 */
			status = "disabled";           /* in zephyr/dts/arm/st/f7/stm32f7.dtsi:270 */
		};

		/* node '/soc/serial@40004400' defined in zephyr/dts/arm/st/f7/stm32f7.dtsi:273 */
		usart2: serial@40004400 {
			compatible = "st,stm32-usart",
			             "st,stm32-uart";                                                  /* in zephyr/dts/arm/st/f7/stm32f7.dtsi:274 */
			reg = < 0x40004400 0x400 >;                                                    /* in zephyr/dts/arm/st/f7/stm32f7.dtsi:275 */
			clocks = < &rcc 0x40 0x20000 >;                                                /* in zephyr/dts/arm/st/f7/stm32f7.dtsi:276 */
			resets = < &rctl 0x411 >;                                                      /* in zephyr/dts/arm/st/f7/stm32f7.dtsi:277 */
			interrupts = < 0x26 0x0 >;                                                     /* in zephyr/dts/arm/st/f7/stm32f7.dtsi:278 */
			status = "disabled";                                                           /* in zephyr/dts/arm/st/f7/stm32f7.dtsi:279 */
			pinctrl-0 = < &usart2_tx_pd5 &usart2_rx_pd6 &usart2_rts_pd4 &usart2_cts_pd3 >; /* in zephyr/boards/st/nucleo_f767zi/nucleo_f767zi.dts:102 */
			pinctrl-names = "default";                                                     /* in zephyr/boards/st/nucleo_f767zi/nucleo_f767zi.dts:106 */
			current-speed = < 0x1c200 >;                                                   /* in zephyr/boards/st/nucleo_f767zi/nucleo_f767zi.dts:107 */
		};

		/* node '/soc/serial@40004800' defined in zephyr/dts/arm/st/f7/stm32f7.dtsi:282 */
		usart3: serial@40004800 {
			compatible = "st,stm32-usart",
			             "st,stm32-uart";                  /* in zephyr/dts/arm/st/f7/stm32f7.dtsi:283 */
			reg = < 0x40004800 0x400 >;                    /* in zephyr/dts/arm/st/f7/stm32f7.dtsi:284 */
			clocks = < &rcc 0x40 0x40000 >;                /* in zephyr/dts/arm/st/f7/stm32f7.dtsi:285 */
			resets = < &rctl 0x412 >;                      /* in zephyr/dts/arm/st/f7/stm32f7.dtsi:286 */
			interrupts = < 0x27 0x0 >;                     /* in zephyr/dts/arm/st/f7/stm32f7.dtsi:287 */
			pinctrl-0 = < &usart3_tx_pd8 &usart3_rx_pd9 >; /* in zephyr/boards/st/nucleo_f767zi/nucleo_f767zi.dts:111 */
			pinctrl-names = "default";                     /* in zephyr/boards/st/nucleo_f767zi/nucleo_f767zi.dts:112 */
			current-speed = < 0x1c200 >;                   /* in zephyr/boards/st/nucleo_f767zi/nucleo_f767zi.dts:113 */
			status = "okay";                               /* in zephyr/boards/st/nucleo_f767zi/nucleo_f767zi.dts:114 */
		};

		/* node '/soc/serial@40004c00' defined in zephyr/dts/arm/st/f7/stm32f7.dtsi:291 */
		uart4: serial@40004c00 {
			compatible = "st,stm32-uart";   /* in zephyr/dts/arm/st/f7/stm32f7.dtsi:292 */
			reg = < 0x40004c00 0x400 >;     /* in zephyr/dts/arm/st/f7/stm32f7.dtsi:293 */
			clocks = < &rcc 0x40 0x80000 >; /* in zephyr/dts/arm/st/f7/stm32f7.dtsi:294 */
			resets = < &rctl 0x413 >;       /* in zephyr/dts/arm/st/f7/stm32f7.dtsi:295 */
			interrupts = < 0x34 0x0 >;      /* in zephyr/dts/arm/st/f7/stm32f7.dtsi:296 */
			status = "disabled";            /* in zephyr/dts/arm/st/f7/stm32f7.dtsi:297 */
		};

		/* node '/soc/serial@40005000' defined in zephyr/dts/arm/st/f7/stm32f7.dtsi:300 */
		uart5: serial@40005000 {
			compatible = "st,stm32-uart";    /* in zephyr/dts/arm/st/f7/stm32f7.dtsi:301 */
			reg = < 0x40005000 0x400 >;      /* in zephyr/dts/arm/st/f7/stm32f7.dtsi:302 */
			clocks = < &rcc 0x40 0x100000 >; /* in zephyr/dts/arm/st/f7/stm32f7.dtsi:303 */
			resets = < &rctl 0x414 >;        /* in zephyr/dts/arm/st/f7/stm32f7.dtsi:304 */
			interrupts = < 0x35 0x0 >;       /* in zephyr/dts/arm/st/f7/stm32f7.dtsi:305 */
			status = "disabled";             /* in zephyr/dts/arm/st/f7/stm32f7.dtsi:306 */
		};

		/* node '/soc/serial@40011400' defined in zephyr/dts/arm/st/f7/stm32f7.dtsi:309 */
		usart6: arduino_serial: serial@40011400 {
			compatible = "st,stm32-usart",
			             "st,stm32-uart";                   /* in zephyr/dts/arm/st/f7/stm32f7.dtsi:310 */
			reg = < 0x40011400 0x400 >;                     /* in zephyr/dts/arm/st/f7/stm32f7.dtsi:311 */
			clocks = < &rcc 0x44 0x20 >;                    /* in zephyr/dts/arm/st/f7/stm32f7.dtsi:312 */
			resets = < &rctl 0x485 >;                       /* in zephyr/dts/arm/st/f7/stm32f7.dtsi:313 */
			interrupts = < 0x47 0x0 >;                      /* in zephyr/dts/arm/st/f7/stm32f7.dtsi:314 */
			pinctrl-0 = < &usart6_tx_pg14 &usart6_rx_pg9 >; /* in zephyr/boards/st/nucleo_f767zi/nucleo_f767zi.dts:118 */
			pinctrl-names = "default";                      /* in zephyr/boards/st/nucleo_f767zi/nucleo_f767zi.dts:119 */
			current-speed = < 0x1c200 >;                    /* in zephyr/boards/st/nucleo_f767zi/nucleo_f767zi.dts:120 */
			status = "okay";                                /* in zephyr/boards/st/nucleo_f767zi/nucleo_f767zi.dts:121 */
		};

		/* node '/soc/serial@40007800' defined in zephyr/dts/arm/st/f7/stm32f7.dtsi:318 */
		uart7: serial@40007800 {
			compatible = "st,stm32-uart";      /* in zephyr/dts/arm/st/f7/stm32f7.dtsi:319 */
			reg = < 0x40007800 0x400 >;        /* in zephyr/dts/arm/st/f7/stm32f7.dtsi:320 */
			clocks = < &rcc 0x40 0x40000000 >; /* in zephyr/dts/arm/st/f7/stm32f7.dtsi:321 */
			resets = < &rctl 0x41e >;          /* in zephyr/dts/arm/st/f7/stm32f7.dtsi:322 */
			interrupts = < 0x52 0x0 >;         /* in zephyr/dts/arm/st/f7/stm32f7.dtsi:323 */
			status = "disabled";               /* in zephyr/dts/arm/st/f7/stm32f7.dtsi:324 */
		};

		/* node '/soc/serial@40007c00' defined in zephyr/dts/arm/st/f7/stm32f7.dtsi:327 */
		uart8: serial@40007c00 {
			compatible = "st,stm32-uart";      /* in zephyr/dts/arm/st/f7/stm32f7.dtsi:328 */
			reg = < 0x40007c00 0x400 >;        /* in zephyr/dts/arm/st/f7/stm32f7.dtsi:329 */
			clocks = < &rcc 0x40 0x80000000 >; /* in zephyr/dts/arm/st/f7/stm32f7.dtsi:330 */
			resets = < &rctl 0x41f >;          /* in zephyr/dts/arm/st/f7/stm32f7.dtsi:331 */
			interrupts = < 0x53 0x0 >;         /* in zephyr/dts/arm/st/f7/stm32f7.dtsi:332 */
			status = "disabled";               /* in zephyr/dts/arm/st/f7/stm32f7.dtsi:333 */
		};

		/* node '/soc/i2c@40005400' defined in zephyr/dts/arm/st/f7/stm32f7.dtsi:336 */
		i2c1: arduino_i2c: i2c@40005400 {
			compatible = "st,stm32-i2c-v2";              /* in zephyr/dts/arm/st/f7/stm32f7.dtsi:337 */
			#address-cells = < 0x1 >;                    /* in zephyr/dts/arm/st/f7/stm32f7.dtsi:339 */
			#size-cells = < 0x0 >;                       /* in zephyr/dts/arm/st/f7/stm32f7.dtsi:340 */
			reg = < 0x40005400 0x400 >;                  /* in zephyr/dts/arm/st/f7/stm32f7.dtsi:341 */
			clocks = < &rcc 0x40 0x200000 >;             /* in zephyr/dts/arm/st/f7/stm32f7.dtsi:342 */
			interrupts = < 0x1f 0x0 >,
			             < 0x20 0x0 >;                   /* in zephyr/dts/arm/st/f7/stm32f7.dtsi:343 */
			interrupt-names = "event",
			                  "error";                   /* in zephyr/dts/arm/st/f7/stm32f7.dtsi:344 */
			pinctrl-0 = < &i2c1_scl_pb8 &i2c1_sda_pb9 >; /* in zephyr/boards/st/nucleo_f767zi/nucleo_f767zi.dts:131 */
			pinctrl-names = "default";                   /* in zephyr/boards/st/nucleo_f767zi/nucleo_f767zi.dts:132 */
			status = "okay";                             /* in zephyr/boards/st/nucleo_f767zi/nucleo_f767zi.dts:133 */
			clock-frequency = < 0x61a80 >;               /* in zephyr/boards/st/nucleo_f767zi/nucleo_f767zi.dts:134 */
		};

		/* node '/soc/i2c@40005800' defined in zephyr/dts/arm/st/f7/stm32f7.dtsi:348 */
		i2c2: i2c@40005800 {
			compatible = "st,stm32-i2c-v2";  /* in zephyr/dts/arm/st/f7/stm32f7.dtsi:349 */
			clock-frequency = < 0x186a0 >;   /* in zephyr/dts/arm/st/f7/stm32f7.dtsi:350 */
			#address-cells = < 0x1 >;        /* in zephyr/dts/arm/st/f7/stm32f7.dtsi:351 */
			#size-cells = < 0x0 >;           /* in zephyr/dts/arm/st/f7/stm32f7.dtsi:352 */
			reg = < 0x40005800 0x400 >;      /* in zephyr/dts/arm/st/f7/stm32f7.dtsi:353 */
			clocks = < &rcc 0x40 0x400000 >; /* in zephyr/dts/arm/st/f7/stm32f7.dtsi:354 */
			interrupts = < 0x21 0x0 >,
			             < 0x22 0x0 >;       /* in zephyr/dts/arm/st/f7/stm32f7.dtsi:355 */
			interrupt-names = "event",
			                  "error";       /* in zephyr/dts/arm/st/f7/stm32f7.dtsi:356 */
			status = "disabled";             /* in zephyr/dts/arm/st/f7/stm32f7.dtsi:357 */
			phandle = < 0x28 >;              /* in zephyr/dts/arm/st/f7/stm32f7.dtsi:974 */
		};

		/* node '/soc/i2c@40005c00' defined in zephyr/dts/arm/st/f7/stm32f7.dtsi:360 */
		i2c3: i2c@40005c00 {
			compatible = "st,stm32-i2c-v2";  /* in zephyr/dts/arm/st/f7/stm32f7.dtsi:361 */
			clock-frequency = < 0x186a0 >;   /* in zephyr/dts/arm/st/f7/stm32f7.dtsi:362 */
			#address-cells = < 0x1 >;        /* in zephyr/dts/arm/st/f7/stm32f7.dtsi:363 */
			#size-cells = < 0x0 >;           /* in zephyr/dts/arm/st/f7/stm32f7.dtsi:364 */
			reg = < 0x40005c00 0x400 >;      /* in zephyr/dts/arm/st/f7/stm32f7.dtsi:365 */
			clocks = < &rcc 0x40 0x800000 >; /* in zephyr/dts/arm/st/f7/stm32f7.dtsi:366 */
			interrupts = < 0x48 0x0 >,
			             < 0x49 0x0 >;       /* in zephyr/dts/arm/st/f7/stm32f7.dtsi:367 */
			interrupt-names = "event",
			                  "error";       /* in zephyr/dts/arm/st/f7/stm32f7.dtsi:368 */
			status = "disabled";             /* in zephyr/dts/arm/st/f7/stm32f7.dtsi:369 */
			phandle = < 0x29 >;              /* in zephyr/dts/arm/st/f7/stm32f7.dtsi:990 */
		};

		/* node '/soc/spi@40013000' defined in zephyr/dts/arm/st/f7/stm32f7.dtsi:372 */
		spi1: arduino_spi: spi@40013000 {
			compatible = "st,stm32-spi-fifo",
			             "st,stm32-spi";                                 /* in zephyr/dts/arm/st/f7/stm32f7.dtsi:373 */
			#address-cells = < 0x1 >;                                    /* in zephyr/dts/arm/st/f7/stm32f7.dtsi:374 */
			#size-cells = < 0x0 >;                                       /* in zephyr/dts/arm/st/f7/stm32f7.dtsi:375 */
			reg = < 0x40013000 0x400 >;                                  /* in zephyr/dts/arm/st/f7/stm32f7.dtsi:376 */
			clocks = < &rcc 0x44 0x1000 >;                               /* in zephyr/dts/arm/st/f7/stm32f7.dtsi:377 */
			interrupts = < 0x23 0x5 >;                                   /* in zephyr/dts/arm/st/f7/stm32f7.dtsi:378 */
			pinctrl-0 = < &spi1_sck_pa5 &spi1_miso_pa6 &spi1_mosi_pa7 >; /* in zephyr/boards/st/nucleo_f767zi/nucleo_f767zi.dts:149 */
			pinctrl-names = "default";                                   /* in zephyr/boards/st/nucleo_f767zi/nucleo_f767zi.dts:150 */
			cs-gpios = < &gpiod 0xe 0x11 >;                              /* in zephyr/boards/st/nucleo_f767zi/nucleo_f767zi.dts:151 */
			status = "okay";                                             /* in zephyr/boards/st/nucleo_f767zi/nucleo_f767zi.dts:156 */
		};

		/* node '/soc/spi@40003800' defined in zephyr/dts/arm/st/f7/stm32f7.dtsi:382 */
		spi2: spi@40003800 {
			compatible = "st,stm32-spi-fifo",
			             "st,stm32-spi";      /* in zephyr/dts/arm/st/f7/stm32f7.dtsi:383 */
			#address-cells = < 0x1 >;         /* in zephyr/dts/arm/st/f7/stm32f7.dtsi:384 */
			#size-cells = < 0x0 >;            /* in zephyr/dts/arm/st/f7/stm32f7.dtsi:385 */
			reg = < 0x40003800 0x400 >;       /* in zephyr/dts/arm/st/f7/stm32f7.dtsi:386 */
			clocks = < &rcc 0x40 0x4000 >;    /* in zephyr/dts/arm/st/f7/stm32f7.dtsi:387 */
			interrupts = < 0x24 0x5 >;        /* in zephyr/dts/arm/st/f7/stm32f7.dtsi:388 */
			status = "disabled";              /* in zephyr/dts/arm/st/f7/stm32f7.dtsi:389 */
		};

		/* node '/soc/spi@40003c00' defined in zephyr/dts/arm/st/f7/stm32f7.dtsi:392 */
		spi3: spi@40003c00 {
			compatible = "st,stm32-spi-fifo",
			             "st,stm32-spi";      /* in zephyr/dts/arm/st/f7/stm32f7.dtsi:393 */
			#address-cells = < 0x1 >;         /* in zephyr/dts/arm/st/f7/stm32f7.dtsi:394 */
			#size-cells = < 0x0 >;            /* in zephyr/dts/arm/st/f7/stm32f7.dtsi:395 */
			reg = < 0x40003c00 0x400 >;       /* in zephyr/dts/arm/st/f7/stm32f7.dtsi:396 */
			clocks = < &rcc 0x40 0x8000 >;    /* in zephyr/dts/arm/st/f7/stm32f7.dtsi:397 */
			interrupts = < 0x33 0x5 >;        /* in zephyr/dts/arm/st/f7/stm32f7.dtsi:398 */
			status = "disabled";              /* in zephyr/dts/arm/st/f7/stm32f7.dtsi:399 */
		};

		/* node '/soc/spi@40013400' defined in zephyr/dts/arm/st/f7/stm32f7.dtsi:402 */
		spi4: spi@40013400 {
			compatible = "st,stm32-spi-fifo",
			             "st,stm32-spi";      /* in zephyr/dts/arm/st/f7/stm32f7.dtsi:403 */
			#address-cells = < 0x1 >;         /* in zephyr/dts/arm/st/f7/stm32f7.dtsi:404 */
			#size-cells = < 0x0 >;            /* in zephyr/dts/arm/st/f7/stm32f7.dtsi:405 */
			reg = < 0x40013400 0x400 >;       /* in zephyr/dts/arm/st/f7/stm32f7.dtsi:406 */
			clocks = < &rcc 0x44 0x2000 >;    /* in zephyr/dts/arm/st/f7/stm32f7.dtsi:407 */
			interrupts = < 0x54 0x5 >;        /* in zephyr/dts/arm/st/f7/stm32f7.dtsi:408 */
			status = "disabled";              /* in zephyr/dts/arm/st/f7/stm32f7.dtsi:409 */
		};

		/* node '/soc/spi@40015000' defined in zephyr/dts/arm/st/f7/stm32f7.dtsi:412 */
		spi5: spi@40015000 {
			compatible = "st,stm32-spi-fifo",
			             "st,stm32-spi";      /* in zephyr/dts/arm/st/f7/stm32f7.dtsi:413 */
			#address-cells = < 0x1 >;         /* in zephyr/dts/arm/st/f7/stm32f7.dtsi:414 */
			#size-cells = < 0x0 >;            /* in zephyr/dts/arm/st/f7/stm32f7.dtsi:415 */
			reg = < 0x40015000 0x400 >;       /* in zephyr/dts/arm/st/f7/stm32f7.dtsi:416 */
			clocks = < &rcc 0x44 0x100000 >;  /* in zephyr/dts/arm/st/f7/stm32f7.dtsi:417 */
			interrupts = < 0x55 0x5 >;        /* in zephyr/dts/arm/st/f7/stm32f7.dtsi:418 */
			status = "disabled";              /* in zephyr/dts/arm/st/f7/stm32f7.dtsi:419 */
		};

		/* node '/soc/can@40006400' defined in zephyr/dts/arm/st/f7/stm32f7.dtsi:422 */
		can1: can@40006400 {
			compatible = "st,stm32-bxcan";             /* in zephyr/dts/arm/st/f7/stm32f7.dtsi:423 */
			reg = < 0x40006400 0x400 >;                /* in zephyr/dts/arm/st/f7/stm32f7.dtsi:424 */
			interrupts = < 0x13 0x0 >,
			             < 0x14 0x0 >,
			             < 0x15 0x0 >,
			             < 0x16 0x0 >;                 /* in zephyr/dts/arm/st/f7/stm32f7.dtsi:425 */
			interrupt-names = "TX",
			                  "RX0",
			                  "RX1",
			                  "SCE";                   /* in zephyr/dts/arm/st/f7/stm32f7.dtsi:426 */
			clocks = < &rcc 0x40 0x2000000 >;          /* in zephyr/dts/arm/st/f7/stm32f7.dtsi:427 */
			pinctrl-0 = < &can1_rx_pd0 &can1_tx_pd1 >; /* in zephyr/boards/st/nucleo_f767zi/nucleo_f767zi.dts:170 */
			pinctrl-names = "default";                 /* in zephyr/boards/st/nucleo_f767zi/nucleo_f767zi.dts:171 */
			status = "okay";                           /* in zephyr/boards/st/nucleo_f767zi/nucleo_f767zi.dts:172 */
		};

		/* node '/soc/timers@40010000' defined in zephyr/dts/arm/st/f7/stm32f7.dtsi:431 */
		timers1: timers@40010000 {
			compatible = "st,stm32-timers"; /* in zephyr/dts/arm/st/f7/stm32f7.dtsi:432 */
			reg = < 0x40010000 0x400 >;     /* in zephyr/dts/arm/st/f7/stm32f7.dtsi:433 */
			clocks = < &rcc 0x44 0x1 >,
			         < &rcc 0xb 0xff >;     /* in zephyr/dts/arm/st/f7/stm32f7.dtsi:434 */
			resets = < &rctl 0x480 >;       /* in zephyr/dts/arm/st/f7/stm32f7.dtsi:436 */
			interrupts = < 0x18 0x0 >,
			             < 0x19 0x0 >,
			             < 0x1a 0x0 >,
			             < 0x1b 0x0 >;      /* in zephyr/dts/arm/st/f7/stm32f7.dtsi:437 */
			interrupt-names = "brk",
			                  "up",
			                  "trgcom",
			                  "cc";         /* in zephyr/dts/arm/st/f7/stm32f7.dtsi:438 */
			st,prescaler = < 0x2710 >;      /* in zephyr/boards/st/nucleo_f767zi/nucleo_f767zi.dts:138 */
			status = "okay";                /* in zephyr/boards/st/nucleo_f767zi/nucleo_f767zi.dts:139 */

			/* node '/soc/timers@40010000/pwm' defined in zephyr/dts/arm/st/f7/stm32f7.dtsi:442 */
			pwm1: pwm {
				compatible = "st,stm32-pwm";    /* in zephyr/dts/arm/st/f7/stm32f7.dtsi:443 */
				#pwm-cells = < 0x3 >;           /* in zephyr/dts/arm/st/f7/stm32f7.dtsi:445 */
				status = "okay";                /* in zephyr/boards/st/nucleo_f767zi/nucleo_f767zi.dts:142 */
				pinctrl-0 = < &tim1_ch3_pe13 >; /* in zephyr/boards/st/nucleo_f767zi/nucleo_f767zi.dts:143 */
				pinctrl-names = "default";      /* in zephyr/boards/st/nucleo_f767zi/nucleo_f767zi.dts:144 */
			};

			/* node '/soc/timers@40010000/qdec' defined in zephyr/dts/arm/st/f7/stm32f7.dtsi:448 */
			qdec {
				compatible = "st,stm32-qdec";    /* in zephyr/dts/arm/st/f7/stm32f7.dtsi:449 */
				st,input-filter-level = < 0x0 >; /* in zephyr/dts/arm/st/f7/stm32f7.dtsi:450 */
				status = "disabled";             /* in zephyr/dts/arm/st/f7/stm32f7.dtsi:451 */
			};
		};

		/* node '/soc/timers@40000000' defined in zephyr/dts/arm/st/f7/stm32f7.dtsi:455 */
		timers2: timers@40000000 {
			compatible = "st,stm32-timers"; /* in zephyr/dts/arm/st/f7/stm32f7.dtsi:456 */
			reg = < 0x40000000 0x400 >;     /* in zephyr/dts/arm/st/f7/stm32f7.dtsi:457 */
			clocks = < &rcc 0x40 0x1 >,
			         < &rcc 0xa 0xff >;     /* in zephyr/dts/arm/st/f7/stm32f7.dtsi:458 */
			resets = < &rctl 0x400 >;       /* in zephyr/dts/arm/st/f7/stm32f7.dtsi:460 */
			interrupts = < 0x1c 0x0 >;      /* in zephyr/dts/arm/st/f7/stm32f7.dtsi:461 */
			interrupt-names = "global";     /* in zephyr/dts/arm/st/f7/stm32f7.dtsi:462 */
			st,prescaler = < 0x0 >;         /* in zephyr/dts/arm/st/f7/stm32f7.dtsi:463 */
			status = "disabled";            /* in zephyr/dts/arm/st/f7/stm32f7.dtsi:464 */

			/* node '/soc/timers@40000000/pwm' defined in zephyr/dts/arm/st/f7/stm32f7.dtsi:466 */
			pwm {
				compatible = "st,stm32-pwm"; /* in zephyr/dts/arm/st/f7/stm32f7.dtsi:467 */
				status = "disabled";         /* in zephyr/dts/arm/st/f7/stm32f7.dtsi:468 */
				#pwm-cells = < 0x3 >;        /* in zephyr/dts/arm/st/f7/stm32f7.dtsi:469 */
			};

			/* node '/soc/timers@40000000/counter' defined in zephyr/dts/arm/st/f7/stm32f7.dtsi:472 */
			counter {
				compatible = "st,stm32-counter"; /* in zephyr/dts/arm/st/f7/stm32f7.dtsi:473 */
				status = "disabled";             /* in zephyr/dts/arm/st/f7/stm32f7.dtsi:474 */
			};

			/* node '/soc/timers@40000000/qdec' defined in zephyr/dts/arm/st/f7/stm32f7.dtsi:477 */
			qdec {
				compatible = "st,stm32-qdec";    /* in zephyr/dts/arm/st/f7/stm32f7.dtsi:478 */
				st,input-filter-level = < 0x0 >; /* in zephyr/dts/arm/st/f7/stm32f7.dtsi:479 */
				status = "disabled";             /* in zephyr/dts/arm/st/f7/stm32f7.dtsi:480 */
			};
		};

		/* node '/soc/timers@40000400' defined in zephyr/dts/arm/st/f7/stm32f7.dtsi:484 */
		timers3: timers@40000400 {
			compatible = "st,stm32-timers"; /* in zephyr/dts/arm/st/f7/stm32f7.dtsi:485 */
			reg = < 0x40000400 0x400 >;     /* in zephyr/dts/arm/st/f7/stm32f7.dtsi:486 */
			clocks = < &rcc 0x40 0x2 >,
			         < &rcc 0xa 0xff >;     /* in zephyr/dts/arm/st/f7/stm32f7.dtsi:487 */
			resets = < &rctl 0x401 >;       /* in zephyr/dts/arm/st/f7/stm32f7.dtsi:489 */
			interrupts = < 0x1d 0x0 >;      /* in zephyr/dts/arm/st/f7/stm32f7.dtsi:490 */
			interrupt-names = "global";     /* in zephyr/dts/arm/st/f7/stm32f7.dtsi:491 */
			st,prescaler = < 0x0 >;         /* in zephyr/dts/arm/st/f7/stm32f7.dtsi:492 */
			status = "disabled";            /* in zephyr/dts/arm/st/f7/stm32f7.dtsi:493 */

			/* node '/soc/timers@40000400/pwm' defined in zephyr/dts/arm/st/f7/stm32f7.dtsi:495 */
			pwm {
				compatible = "st,stm32-pwm"; /* in zephyr/dts/arm/st/f7/stm32f7.dtsi:496 */
				status = "disabled";         /* in zephyr/dts/arm/st/f7/stm32f7.dtsi:497 */
				#pwm-cells = < 0x3 >;        /* in zephyr/dts/arm/st/f7/stm32f7.dtsi:498 */
			};

			/* node '/soc/timers@40000400/counter' defined in zephyr/dts/arm/st/f7/stm32f7.dtsi:501 */
			counter {
				compatible = "st,stm32-counter"; /* in zephyr/dts/arm/st/f7/stm32f7.dtsi:502 */
				status = "disabled";             /* in zephyr/dts/arm/st/f7/stm32f7.dtsi:503 */
			};

			/* node '/soc/timers@40000400/qdec' defined in zephyr/dts/arm/st/f7/stm32f7.dtsi:506 */
			qdec {
				compatible = "st,stm32-qdec";    /* in zephyr/dts/arm/st/f7/stm32f7.dtsi:507 */
				st,input-filter-level = < 0x0 >; /* in zephyr/dts/arm/st/f7/stm32f7.dtsi:508 */
				status = "disabled";             /* in zephyr/dts/arm/st/f7/stm32f7.dtsi:509 */
			};
		};

		/* node '/soc/timers@40000800' defined in zephyr/dts/arm/st/f7/stm32f7.dtsi:513 */
		timers4: timers@40000800 {
			compatible = "st,stm32-timers"; /* in zephyr/dts/arm/st/f7/stm32f7.dtsi:514 */
			reg = < 0x40000800 0x400 >;     /* in zephyr/dts/arm/st/f7/stm32f7.dtsi:515 */
			clocks = < &rcc 0x40 0x4 >,
			         < &rcc 0xa 0xff >;     /* in zephyr/dts/arm/st/f7/stm32f7.dtsi:516 */
			resets = < &rctl 0x402 >;       /* in zephyr/dts/arm/st/f7/stm32f7.dtsi:518 */
			interrupts = < 0x1e 0x0 >;      /* in zephyr/dts/arm/st/f7/stm32f7.dtsi:519 */
			interrupt-names = "global";     /* in zephyr/dts/arm/st/f7/stm32f7.dtsi:520 */
			st,prescaler = < 0x0 >;         /* in zephyr/dts/arm/st/f7/stm32f7.dtsi:521 */
			status = "disabled";            /* in zephyr/dts/arm/st/f7/stm32f7.dtsi:522 */

			/* node '/soc/timers@40000800/pwm' defined in zephyr/dts/arm/st/f7/stm32f7.dtsi:524 */
			pwm {
				compatible = "st,stm32-pwm"; /* in zephyr/dts/arm/st/f7/stm32f7.dtsi:525 */
				status = "disabled";         /* in zephyr/dts/arm/st/f7/stm32f7.dtsi:526 */
				#pwm-cells = < 0x3 >;        /* in zephyr/dts/arm/st/f7/stm32f7.dtsi:527 */
			};

			/* node '/soc/timers@40000800/counter' defined in zephyr/dts/arm/st/f7/stm32f7.dtsi:530 */
			counter {
				compatible = "st,stm32-counter"; /* in zephyr/dts/arm/st/f7/stm32f7.dtsi:531 */
				status = "disabled";             /* in zephyr/dts/arm/st/f7/stm32f7.dtsi:532 */
			};

			/* node '/soc/timers@40000800/qdec' defined in zephyr/dts/arm/st/f7/stm32f7.dtsi:535 */
			qdec {
				compatible = "st,stm32-qdec";    /* in zephyr/dts/arm/st/f7/stm32f7.dtsi:536 */
				st,input-filter-level = < 0x0 >; /* in zephyr/dts/arm/st/f7/stm32f7.dtsi:537 */
				status = "disabled";             /* in zephyr/dts/arm/st/f7/stm32f7.dtsi:538 */
			};
		};

		/* node '/soc/timers@40000c00' defined in zephyr/dts/arm/st/f7/stm32f7.dtsi:542 */
		timers5: timers@40000c00 {
			compatible = "st,stm32-timers"; /* in zephyr/dts/arm/st/f7/stm32f7.dtsi:543 */
			reg = < 0x40000c00 0x400 >;     /* in zephyr/dts/arm/st/f7/stm32f7.dtsi:544 */
			clocks = < &rcc 0x40 0x8 >,
			         < &rcc 0xa 0xff >;     /* in zephyr/dts/arm/st/f7/stm32f7.dtsi:545 */
			resets = < &rctl 0x403 >;       /* in zephyr/dts/arm/st/f7/stm32f7.dtsi:547 */
			interrupts = < 0x32 0x0 >;      /* in zephyr/dts/arm/st/f7/stm32f7.dtsi:548 */
			interrupt-names = "global";     /* in zephyr/dts/arm/st/f7/stm32f7.dtsi:549 */
			st,prescaler = < 0x0 >;         /* in zephyr/dts/arm/st/f7/stm32f7.dtsi:550 */
			status = "disabled";            /* in zephyr/dts/arm/st/f7/stm32f7.dtsi:551 */

			/* node '/soc/timers@40000c00/pwm' defined in zephyr/dts/arm/st/f7/stm32f7.dtsi:553 */
			pwm {
				compatible = "st,stm32-pwm"; /* in zephyr/dts/arm/st/f7/stm32f7.dtsi:554 */
				status = "disabled";         /* in zephyr/dts/arm/st/f7/stm32f7.dtsi:555 */
				#pwm-cells = < 0x3 >;        /* in zephyr/dts/arm/st/f7/stm32f7.dtsi:556 */
			};

			/* node '/soc/timers@40000c00/counter' defined in zephyr/dts/arm/st/f7/stm32f7.dtsi:559 */
			counter {
				compatible = "st,stm32-counter"; /* in zephyr/dts/arm/st/f7/stm32f7.dtsi:560 */
				status = "disabled";             /* in zephyr/dts/arm/st/f7/stm32f7.dtsi:561 */
			};

			/* node '/soc/timers@40000c00/qdec' defined in zephyr/dts/arm/st/f7/stm32f7.dtsi:564 */
			qdec {
				compatible = "st,stm32-qdec";    /* in zephyr/dts/arm/st/f7/stm32f7.dtsi:565 */
				st,input-filter-level = < 0x0 >; /* in zephyr/dts/arm/st/f7/stm32f7.dtsi:566 */
				status = "disabled";             /* in zephyr/dts/arm/st/f7/stm32f7.dtsi:567 */
			};
		};

		/* node '/soc/timers@40001000' defined in zephyr/dts/arm/st/f7/stm32f7.dtsi:571 */
		timers6: timers@40001000 {
			compatible = "st,stm32-timers"; /* in zephyr/dts/arm/st/f7/stm32f7.dtsi:572 */
			reg = < 0x40001000 0x400 >;     /* in zephyr/dts/arm/st/f7/stm32f7.dtsi:573 */
			clocks = < &rcc 0x40 0x10 >,
			         < &rcc 0xa 0xff >;     /* in zephyr/dts/arm/st/f7/stm32f7.dtsi:574 */
			resets = < &rctl 0x404 >;       /* in zephyr/dts/arm/st/f7/stm32f7.dtsi:576 */
			interrupts = < 0x36 0x0 >;      /* in zephyr/dts/arm/st/f7/stm32f7.dtsi:577 */
			interrupt-names = "global";     /* in zephyr/dts/arm/st/f7/stm32f7.dtsi:578 */
			st,prescaler = < 0x0 >;         /* in zephyr/dts/arm/st/f7/stm32f7.dtsi:579 */
			status = "disabled";            /* in zephyr/dts/arm/st/f7/stm32f7.dtsi:580 */

			/* node '/soc/timers@40001000/counter' defined in zephyr/dts/arm/st/f7/stm32f7.dtsi:582 */
			counter {
				compatible = "st,stm32-counter"; /* in zephyr/dts/arm/st/f7/stm32f7.dtsi:583 */
				status = "disabled";             /* in zephyr/dts/arm/st/f7/stm32f7.dtsi:584 */
			};
		};

		/* node '/soc/timers@40001400' defined in zephyr/dts/arm/st/f7/stm32f7.dtsi:588 */
		timers7: timers@40001400 {
			compatible = "st,stm32-timers"; /* in zephyr/dts/arm/st/f7/stm32f7.dtsi:589 */
			reg = < 0x40001400 0x400 >;     /* in zephyr/dts/arm/st/f7/stm32f7.dtsi:590 */
			clocks = < &rcc 0x40 0x20 >,
			         < &rcc 0xa 0xff >;     /* in zephyr/dts/arm/st/f7/stm32f7.dtsi:591 */
			resets = < &rctl 0x405 >;       /* in zephyr/dts/arm/st/f7/stm32f7.dtsi:593 */
			interrupts = < 0x37 0x0 >;      /* in zephyr/dts/arm/st/f7/stm32f7.dtsi:594 */
			interrupt-names = "global";     /* in zephyr/dts/arm/st/f7/stm32f7.dtsi:595 */
			st,prescaler = < 0x0 >;         /* in zephyr/dts/arm/st/f7/stm32f7.dtsi:596 */
			status = "disabled";            /* in zephyr/dts/arm/st/f7/stm32f7.dtsi:597 */

			/* node '/soc/timers@40001400/counter' defined in zephyr/dts/arm/st/f7/stm32f7.dtsi:599 */
			counter {
				compatible = "st,stm32-counter"; /* in zephyr/dts/arm/st/f7/stm32f7.dtsi:600 */
				status = "disabled";             /* in zephyr/dts/arm/st/f7/stm32f7.dtsi:601 */
			};
		};

		/* node '/soc/timers@40010400' defined in zephyr/dts/arm/st/f7/stm32f7.dtsi:605 */
		timers8: timers@40010400 {
			compatible = "st,stm32-timers"; /* in zephyr/dts/arm/st/f7/stm32f7.dtsi:606 */
			reg = < 0x40010400 0x400 >;     /* in zephyr/dts/arm/st/f7/stm32f7.dtsi:607 */
			clocks = < &rcc 0x44 0x2 >,
			         < &rcc 0xb 0xff >;     /* in zephyr/dts/arm/st/f7/stm32f7.dtsi:608 */
			resets = < &rctl 0x481 >;       /* in zephyr/dts/arm/st/f7/stm32f7.dtsi:610 */
			interrupts = < 0x2b 0x0 >,
			             < 0x2c 0x0 >,
			             < 0x2d 0x0 >,
			             < 0x2e 0x0 >;      /* in zephyr/dts/arm/st/f7/stm32f7.dtsi:611 */
			interrupt-names = "brk",
			                  "up",
			                  "trgcom",
			                  "cc";         /* in zephyr/dts/arm/st/f7/stm32f7.dtsi:612 */
			st,prescaler = < 0x0 >;         /* in zephyr/dts/arm/st/f7/stm32f7.dtsi:613 */
			status = "disabled";            /* in zephyr/dts/arm/st/f7/stm32f7.dtsi:614 */

			/* node '/soc/timers@40010400/pwm' defined in zephyr/dts/arm/st/f7/stm32f7.dtsi:616 */
			pwm {
				compatible = "st,stm32-pwm"; /* in zephyr/dts/arm/st/f7/stm32f7.dtsi:617 */
				status = "disabled";         /* in zephyr/dts/arm/st/f7/stm32f7.dtsi:618 */
				#pwm-cells = < 0x3 >;        /* in zephyr/dts/arm/st/f7/stm32f7.dtsi:619 */
			};

			/* node '/soc/timers@40010400/qdec' defined in zephyr/dts/arm/st/f7/stm32f7.dtsi:622 */
			qdec {
				compatible = "st,stm32-qdec";    /* in zephyr/dts/arm/st/f7/stm32f7.dtsi:623 */
				st,input-filter-level = < 0x0 >; /* in zephyr/dts/arm/st/f7/stm32f7.dtsi:624 */
				status = "disabled";             /* in zephyr/dts/arm/st/f7/stm32f7.dtsi:625 */
			};
		};

		/* node '/soc/timers@40014000' defined in zephyr/dts/arm/st/f7/stm32f7.dtsi:629 */
		timers9: timers@40014000 {
			compatible = "st,stm32-timers"; /* in zephyr/dts/arm/st/f7/stm32f7.dtsi:630 */
			reg = < 0x40014000 0x400 >;     /* in zephyr/dts/arm/st/f7/stm32f7.dtsi:631 */
			clocks = < &rcc 0x44 0x10000 >,
			         < &rcc 0xb 0xff >;     /* in zephyr/dts/arm/st/f7/stm32f7.dtsi:632 */
			resets = < &rctl 0x490 >;       /* in zephyr/dts/arm/st/f7/stm32f7.dtsi:634 */
			interrupts = < 0x18 0x0 >;      /* in zephyr/dts/arm/st/f7/stm32f7.dtsi:635 */
			interrupt-names = "global";     /* in zephyr/dts/arm/st/f7/stm32f7.dtsi:636 */
			st,prescaler = < 0x0 >;         /* in zephyr/dts/arm/st/f7/stm32f7.dtsi:637 */
			status = "disabled";            /* in zephyr/dts/arm/st/f7/stm32f7.dtsi:638 */

			/* node '/soc/timers@40014000/pwm' defined in zephyr/dts/arm/st/f7/stm32f7.dtsi:640 */
			pwm {
				compatible = "st,stm32-pwm"; /* in zephyr/dts/arm/st/f7/stm32f7.dtsi:641 */
				status = "disabled";         /* in zephyr/dts/arm/st/f7/stm32f7.dtsi:642 */
				#pwm-cells = < 0x3 >;        /* in zephyr/dts/arm/st/f7/stm32f7.dtsi:643 */
			};

			/* node '/soc/timers@40014000/counter' defined in zephyr/dts/arm/st/f7/stm32f7.dtsi:646 */
			counter {
				compatible = "st,stm32-counter"; /* in zephyr/dts/arm/st/f7/stm32f7.dtsi:647 */
				status = "disabled";             /* in zephyr/dts/arm/st/f7/stm32f7.dtsi:648 */
			};
		};

		/* node '/soc/timers@40014400' defined in zephyr/dts/arm/st/f7/stm32f7.dtsi:652 */
		timers10: timers@40014400 {
			compatible = "st,stm32-timers"; /* in zephyr/dts/arm/st/f7/stm32f7.dtsi:653 */
			reg = < 0x40014400 0x400 >;     /* in zephyr/dts/arm/st/f7/stm32f7.dtsi:654 */
			clocks = < &rcc 0x44 0x20000 >,
			         < &rcc 0xb 0xff >;     /* in zephyr/dts/arm/st/f7/stm32f7.dtsi:655 */
			resets = < &rctl 0x491 >;       /* in zephyr/dts/arm/st/f7/stm32f7.dtsi:657 */
			interrupts = < 0x19 0x0 >;      /* in zephyr/dts/arm/st/f7/stm32f7.dtsi:658 */
			interrupt-names = "global";     /* in zephyr/dts/arm/st/f7/stm32f7.dtsi:659 */
			st,prescaler = < 0x0 >;         /* in zephyr/dts/arm/st/f7/stm32f7.dtsi:660 */
			status = "disabled";            /* in zephyr/dts/arm/st/f7/stm32f7.dtsi:661 */

			/* node '/soc/timers@40014400/pwm' defined in zephyr/dts/arm/st/f7/stm32f7.dtsi:663 */
			pwm {
				compatible = "st,stm32-pwm"; /* in zephyr/dts/arm/st/f7/stm32f7.dtsi:664 */
				status = "disabled";         /* in zephyr/dts/arm/st/f7/stm32f7.dtsi:665 */
				#pwm-cells = < 0x3 >;        /* in zephyr/dts/arm/st/f7/stm32f7.dtsi:666 */
			};

			/* node '/soc/timers@40014400/counter' defined in zephyr/dts/arm/st/f7/stm32f7.dtsi:669 */
			counter {
				compatible = "st,stm32-counter"; /* in zephyr/dts/arm/st/f7/stm32f7.dtsi:670 */
				status = "disabled";             /* in zephyr/dts/arm/st/f7/stm32f7.dtsi:671 */
			};
		};

		/* node '/soc/timers@40014800' defined in zephyr/dts/arm/st/f7/stm32f7.dtsi:675 */
		timers11: timers@40014800 {
			compatible = "st,stm32-timers"; /* in zephyr/dts/arm/st/f7/stm32f7.dtsi:676 */
			reg = < 0x40014800 0x400 >;     /* in zephyr/dts/arm/st/f7/stm32f7.dtsi:677 */
			clocks = < &rcc 0x44 0x40000 >,
			         < &rcc 0xb 0xff >;     /* in zephyr/dts/arm/st/f7/stm32f7.dtsi:678 */
			resets = < &rctl 0x492 >;       /* in zephyr/dts/arm/st/f7/stm32f7.dtsi:680 */
			interrupts = < 0x1a 0x0 >;      /* in zephyr/dts/arm/st/f7/stm32f7.dtsi:681 */
			interrupt-names = "global";     /* in zephyr/dts/arm/st/f7/stm32f7.dtsi:682 */
			st,prescaler = < 0x0 >;         /* in zephyr/dts/arm/st/f7/stm32f7.dtsi:683 */
			status = "disabled";            /* in zephyr/dts/arm/st/f7/stm32f7.dtsi:684 */

			/* node '/soc/timers@40014800/pwm' defined in zephyr/dts/arm/st/f7/stm32f7.dtsi:686 */
			pwm {
				compatible = "st,stm32-pwm"; /* in zephyr/dts/arm/st/f7/stm32f7.dtsi:687 */
				status = "disabled";         /* in zephyr/dts/arm/st/f7/stm32f7.dtsi:688 */
				#pwm-cells = < 0x3 >;        /* in zephyr/dts/arm/st/f7/stm32f7.dtsi:689 */
			};

			/* node '/soc/timers@40014800/counter' defined in zephyr/dts/arm/st/f7/stm32f7.dtsi:692 */
			counter {
				compatible = "st,stm32-counter"; /* in zephyr/dts/arm/st/f7/stm32f7.dtsi:693 */
				status = "disabled";             /* in zephyr/dts/arm/st/f7/stm32f7.dtsi:694 */
			};
		};

		/* node '/soc/timers@40001800' defined in zephyr/dts/arm/st/f7/stm32f7.dtsi:698 */
		timers12: timers@40001800 {
			compatible = "st,stm32-timers"; /* in zephyr/dts/arm/st/f7/stm32f7.dtsi:699 */
			reg = < 0x40001800 0x400 >;     /* in zephyr/dts/arm/st/f7/stm32f7.dtsi:700 */
			clocks = < &rcc 0x40 0x40 >,
			         < &rcc 0xa 0xff >;     /* in zephyr/dts/arm/st/f7/stm32f7.dtsi:701 */
			resets = < &rctl 0x406 >;       /* in zephyr/dts/arm/st/f7/stm32f7.dtsi:703 */
			interrupts = < 0x2b 0x0 >;      /* in zephyr/dts/arm/st/f7/stm32f7.dtsi:704 */
			interrupt-names = "global";     /* in zephyr/dts/arm/st/f7/stm32f7.dtsi:705 */
			st,prescaler = < 0x0 >;         /* in zephyr/dts/arm/st/f7/stm32f7.dtsi:706 */
			status = "disabled";            /* in zephyr/dts/arm/st/f7/stm32f7.dtsi:707 */

			/* node '/soc/timers@40001800/pwm' defined in zephyr/dts/arm/st/f7/stm32f7.dtsi:709 */
			pwm {
				compatible = "st,stm32-pwm"; /* in zephyr/dts/arm/st/f7/stm32f7.dtsi:710 */
				status = "disabled";         /* in zephyr/dts/arm/st/f7/stm32f7.dtsi:711 */
				#pwm-cells = < 0x3 >;        /* in zephyr/dts/arm/st/f7/stm32f7.dtsi:712 */
			};

			/* node '/soc/timers@40001800/counter' defined in zephyr/dts/arm/st/f7/stm32f7.dtsi:715 */
			counter {
				compatible = "st,stm32-counter"; /* in zephyr/dts/arm/st/f7/stm32f7.dtsi:716 */
				status = "disabled";             /* in zephyr/dts/arm/st/f7/stm32f7.dtsi:717 */
			};
		};

		/* node '/soc/timers@40001c00' defined in zephyr/dts/arm/st/f7/stm32f7.dtsi:721 */
		timers13: timers@40001c00 {
			compatible = "st,stm32-timers"; /* in zephyr/dts/arm/st/f7/stm32f7.dtsi:722 */
			reg = < 0x40001c00 0x400 >;     /* in zephyr/dts/arm/st/f7/stm32f7.dtsi:723 */
			clocks = < &rcc 0x40 0x80 >,
			         < &rcc 0xa 0xff >;     /* in zephyr/dts/arm/st/f7/stm32f7.dtsi:724 */
			resets = < &rctl 0x407 >;       /* in zephyr/dts/arm/st/f7/stm32f7.dtsi:726 */
			interrupts = < 0x2c 0x0 >;      /* in zephyr/dts/arm/st/f7/stm32f7.dtsi:727 */
			interrupt-names = "global";     /* in zephyr/dts/arm/st/f7/stm32f7.dtsi:728 */
			st,prescaler = < 0x0 >;         /* in zephyr/dts/arm/st/f7/stm32f7.dtsi:729 */
			status = "disabled";            /* in zephyr/dts/arm/st/f7/stm32f7.dtsi:730 */

			/* node '/soc/timers@40001c00/pwm' defined in zephyr/dts/arm/st/f7/stm32f7.dtsi:732 */
			pwm {
				compatible = "st,stm32-pwm"; /* in zephyr/dts/arm/st/f7/stm32f7.dtsi:733 */
				status = "disabled";         /* in zephyr/dts/arm/st/f7/stm32f7.dtsi:734 */
				#pwm-cells = < 0x3 >;        /* in zephyr/dts/arm/st/f7/stm32f7.dtsi:735 */
			};

			/* node '/soc/timers@40001c00/counter' defined in zephyr/dts/arm/st/f7/stm32f7.dtsi:738 */
			counter {
				compatible = "st,stm32-counter"; /* in zephyr/dts/arm/st/f7/stm32f7.dtsi:739 */
				status = "disabled";             /* in zephyr/dts/arm/st/f7/stm32f7.dtsi:740 */
			};
		};

		/* node '/soc/timers@40002000' defined in zephyr/dts/arm/st/f7/stm32f7.dtsi:744 */
		timers14: timers@40002000 {
			compatible = "st,stm32-timers"; /* in zephyr/dts/arm/st/f7/stm32f7.dtsi:745 */
			reg = < 0x40002000 0x400 >;     /* in zephyr/dts/arm/st/f7/stm32f7.dtsi:746 */
			clocks = < &rcc 0x40 0x100 >,
			         < &rcc 0xa 0xff >;     /* in zephyr/dts/arm/st/f7/stm32f7.dtsi:747 */
			resets = < &rctl 0x408 >;       /* in zephyr/dts/arm/st/f7/stm32f7.dtsi:749 */
			interrupts = < 0x2d 0x0 >;      /* in zephyr/dts/arm/st/f7/stm32f7.dtsi:750 */
			interrupt-names = "global";     /* in zephyr/dts/arm/st/f7/stm32f7.dtsi:751 */
			st,prescaler = < 0x0 >;         /* in zephyr/dts/arm/st/f7/stm32f7.dtsi:752 */
			status = "disabled";            /* in zephyr/dts/arm/st/f7/stm32f7.dtsi:753 */

			/* node '/soc/timers@40002000/pwm' defined in zephyr/dts/arm/st/f7/stm32f7.dtsi:755 */
			pwm {
				compatible = "st,stm32-pwm"; /* in zephyr/dts/arm/st/f7/stm32f7.dtsi:756 */
				status = "disabled";         /* in zephyr/dts/arm/st/f7/stm32f7.dtsi:757 */
				#pwm-cells = < 0x3 >;        /* in zephyr/dts/arm/st/f7/stm32f7.dtsi:758 */
			};

			/* node '/soc/timers@40002000/counter' defined in zephyr/dts/arm/st/f7/stm32f7.dtsi:761 */
			counter {
				compatible = "st,stm32-counter"; /* in zephyr/dts/arm/st/f7/stm32f7.dtsi:762 */
				status = "disabled";             /* in zephyr/dts/arm/st/f7/stm32f7.dtsi:763 */
			};
		};

		/* node '/soc/usb@50000000' defined in zephyr/dts/arm/st/f7/stm32f7.dtsi:767 */
		usbotg_fs: zephyr_udc0: usb@50000000 {
			compatible = "st,stm32-otgfs";                           /* in zephyr/dts/arm/st/f7/stm32f7.dtsi:768 */
			reg = < 0x50000000 0x40000 >;                            /* in zephyr/dts/arm/st/f7/stm32f7.dtsi:769 */
			interrupts = < 0x43 0x0 >;                               /* in zephyr/dts/arm/st/f7/stm32f7.dtsi:770 */
			interrupt-names = "otgfs";                               /* in zephyr/dts/arm/st/f7/stm32f7.dtsi:771 */
			num-bidir-endpoints = < 0x6 >;                           /* in zephyr/dts/arm/st/f7/stm32f7.dtsi:772 */
			ram-size = < 0x500 >;                                    /* in zephyr/dts/arm/st/f7/stm32f7.dtsi:773 */
			maximum-speed = "full-speed";                            /* in zephyr/dts/arm/st/f7/stm32f7.dtsi:774 */
			phys = < &otgfs_phy >;                                   /* in zephyr/dts/arm/st/f7/stm32f7.dtsi:775 */
			clocks = < &rcc 0x34 0x80 >,
			         < &rcc 0x7 0x1b0090 >;                          /* in zephyr/dts/arm/st/f7/stm32f7.dtsi:776 */
			pinctrl-0 = < &usb_otg_fs_dm_pa11 &usb_otg_fs_dp_pa12 >; /* in zephyr/boards/st/nucleo_f767zi/nucleo_f767zi.dts:125 */
			pinctrl-names = "default";                               /* in zephyr/boards/st/nucleo_f767zi/nucleo_f767zi.dts:126 */
			status = "okay";                                         /* in zephyr/boards/st/nucleo_f767zi/nucleo_f767zi.dts:127 */
		};

		/* node '/soc/usb@40040000' defined in zephyr/dts/arm/st/f7/stm32f7.dtsi:781 */
		usbotg_hs: usb@40040000 {
			compatible = "st,stm32-otghs";     /* in zephyr/dts/arm/st/f7/stm32f7.dtsi:782 */
			reg = < 0x40040000 0x40000 >;      /* in zephyr/dts/arm/st/f7/stm32f7.dtsi:783 */
			interrupts = < 0x4d 0x0 >,
			             < 0x4a 0x0 >,
			             < 0x4b 0x0 >;         /* in zephyr/dts/arm/st/f7/stm32f7.dtsi:784 */
			interrupt-names = "otghs",
			                  "ep1_out",
			                  "ep1_in";        /* in zephyr/dts/arm/st/f7/stm32f7.dtsi:785 */
			num-bidir-endpoints = < 0x9 >;     /* in zephyr/dts/arm/st/f7/stm32f7.dtsi:786 */
			ram-size = < 0x1000 >;             /* in zephyr/dts/arm/st/f7/stm32f7.dtsi:787 */
			maximum-speed = "full-speed";      /* in zephyr/dts/arm/st/f7/stm32f7.dtsi:788 */
			clocks = < &rcc 0x30 0x20000000 >,
			         < &rcc 0x7 0x1b0090 >;    /* in zephyr/dts/arm/st/f7/stm32f7.dtsi:789 */
			phys = < &otghs_fs_phy >;          /* in zephyr/dts/arm/st/f7/stm32f7.dtsi:791 */
			status = "disabled";               /* in zephyr/dts/arm/st/f7/stm32f7.dtsi:792 */
		};

		/* node '/soc/rtc@40002800' defined in zephyr/dts/arm/st/f7/stm32f7.dtsi:795 */
		rtc: rtc@40002800 {
			compatible = "st,stm32-rtc";       /* in zephyr/dts/arm/st/f7/stm32f7.dtsi:796 */
			reg = < 0x40002800 0x300 >;        /* in zephyr/dts/arm/st/f7/stm32f7.dtsi:797 */
			interrupts = < 0x29 0x0 >;         /* in zephyr/dts/arm/st/f7/stm32f7.dtsi:798 */
			prescaler = < 0x8000 >;            /* in zephyr/dts/arm/st/f7/stm32f7.dtsi:800 */
			alarms-count = < 0x2 >;            /* in zephyr/dts/arm/st/f7/stm32f7.dtsi:801 */
			alrm-exti-line = < 0x11 >;         /* in zephyr/dts/arm/st/f7/stm32f7.dtsi:802 */
			clocks = < &rcc 0x40 0x10000000 >,
			         < &rcc 0x3 0x2280070 >;   /* in zephyr/boards/st/nucleo_f767zi/nucleo_f767zi.dts:164 */
			status = "okay";                   /* in zephyr/boards/st/nucleo_f767zi/nucleo_f767zi.dts:166 */

			/* node '/soc/rtc@40002800/backup_regs' defined in zephyr/dts/arm/st/f7/stm32f7.dtsi:805 */
			bbram: backup_regs {
				compatible = "st,stm32-bbram"; /* in zephyr/dts/arm/st/f7/stm32f7.dtsi:806 */
				st,backup-regs = < 0x20 >;     /* in zephyr/dts/arm/st/f7/stm32f7.dtsi:807 */
				status = "disabled";           /* in zephyr/dts/arm/st/f7/stm32f7.dtsi:808 */
			};
		};

		/* node '/soc/adc@40012000' defined in zephyr/dts/arm/st/f7/stm32f7.dtsi:812 */
		adc1: adc@40012000 {
			compatible = "st,stm32f4-adc",
			             "st,stm32-adc";                                 /* in zephyr/dts/arm/st/f7/stm32f7.dtsi:813 */
			reg = < 0x40012000 0x50 >;                                   /* in zephyr/dts/arm/st/f7/stm32f7.dtsi:814 */
			clocks = < &rcc 0x44 0x100 >;                                /* in zephyr/dts/arm/st/f7/stm32f7.dtsi:815 */
			clock-names = "adcx";                                        /* in zephyr/dts/arm/st/f7/stm32f7.dtsi:816 */
			interrupts = < 0x12 0x0 >;                                   /* in zephyr/dts/arm/st/f7/stm32f7.dtsi:817 */
			#io-channel-cells = < 0x1 >;                                 /* in zephyr/dts/arm/st/f7/stm32f7.dtsi:818 */
			resolutions = < 0x607804 0x517804 0x427804 0x337804 >;       /* in zephyr/dts/arm/st/f7/stm32f7.dtsi:819 */
			sampling-times = < 0x3 0xf 0x1c 0x38 0x54 0x70 0x90 0x1e0 >; /* in zephyr/dts/arm/st/f7/stm32f7.dtsi:823 */
			st,adc-sequencer = "programmable";                           /* in zephyr/dts/arm/st/f7/stm32f7.dtsi:825 */
			st,adc-oversampler = "none";                                 /* in zephyr/dts/arm/st/f7/stm32f7.dtsi:826 */
			st,adc-internal-regulator = "none";                          /* in zephyr/dts/arm/st/f7/stm32f7.dtsi:827 */
			pinctrl-0 = < &adc1_in0_pa0 >;                               /* in zephyr/boards/st/nucleo_f767zi/nucleo_f767zi.dts:176 */
			pinctrl-names = "default";                                   /* in zephyr/boards/st/nucleo_f767zi/nucleo_f767zi.dts:177 */
			st,adc-clock-source = "SYNC";                                /* in zephyr/boards/st/nucleo_f767zi/nucleo_f767zi.dts:178 */
			st,adc-prescaler = < 0x2 >;                                  /* in zephyr/boards/st/nucleo_f767zi/nucleo_f767zi.dts:179 */
			status = "okay";                                             /* in zephyr/boards/st/nucleo_f767zi/nucleo_f767zi.dts:180 */
			phandle = < 0x27 >;                                          /* in zephyr/dts/arm/st/f7/stm32f7.dtsi:941 */
		};

		/* node '/soc/adc@40012100' defined in zephyr/dts/arm/st/f7/stm32f7.dtsi:831 */
		adc2: adc@40012100 {
			compatible = "st,stm32f4-adc",
			             "st,stm32-adc";                                 /* in zephyr/dts/arm/st/f7/stm32f7.dtsi:832 */
			reg = < 0x40012100 0x50 >;                                   /* in zephyr/dts/arm/st/f7/stm32f7.dtsi:833 */
			clocks = < &rcc 0x44 0x200 >;                                /* in zephyr/dts/arm/st/f7/stm32f7.dtsi:834 */
			clock-names = "adcx";                                        /* in zephyr/dts/arm/st/f7/stm32f7.dtsi:835 */
			interrupts = < 0x12 0x0 >;                                   /* in zephyr/dts/arm/st/f7/stm32f7.dtsi:836 */
			#io-channel-cells = < 0x1 >;                                 /* in zephyr/dts/arm/st/f7/stm32f7.dtsi:837 */
			resolutions = < 0x607804 0x517804 0x427804 0x337804 >;       /* in zephyr/dts/arm/st/f7/stm32f7.dtsi:838 */
			sampling-times = < 0x3 0xf 0x1c 0x38 0x54 0x70 0x90 0x1e0 >; /* in zephyr/dts/arm/st/f7/stm32f7.dtsi:842 */
			st,adc-clock-source = "SYNC";                                /* in zephyr/dts/arm/st/f7/stm32f7.dtsi:843 */
			st,adc-sequencer = "programmable";                           /* in zephyr/dts/arm/st/f7/stm32f7.dtsi:844 */
			st,adc-oversampler = "none";                                 /* in zephyr/dts/arm/st/f7/stm32f7.dtsi:845 */
			st,adc-internal-regulator = "none";                          /* in zephyr/dts/arm/st/f7/stm32f7.dtsi:846 */
			status = "disabled";                                         /* in zephyr/dts/arm/st/f7/stm32f7.dtsi:847 */
		};

		/* node '/soc/adc@40012200' defined in zephyr/dts/arm/st/f7/stm32f7.dtsi:850 */
		adc3: adc@40012200 {
			compatible = "st,stm32f4-adc",
			             "st,stm32-adc";                                 /* in zephyr/dts/arm/st/f7/stm32f7.dtsi:851 */
			reg = < 0x40012200 0x50 >;                                   /* in zephyr/dts/arm/st/f7/stm32f7.dtsi:852 */
			clocks = < &rcc 0x44 0x400 >;                                /* in zephyr/dts/arm/st/f7/stm32f7.dtsi:853 */
			clock-names = "adcx";                                        /* in zephyr/dts/arm/st/f7/stm32f7.dtsi:854 */
			interrupts = < 0x12 0x0 >;                                   /* in zephyr/dts/arm/st/f7/stm32f7.dtsi:855 */
			#io-channel-cells = < 0x1 >;                                 /* in zephyr/dts/arm/st/f7/stm32f7.dtsi:856 */
			resolutions = < 0x607804 0x517804 0x427804 0x337804 >;       /* in zephyr/dts/arm/st/f7/stm32f7.dtsi:857 */
			sampling-times = < 0x3 0xf 0x1c 0x38 0x54 0x70 0x90 0x1e0 >; /* in zephyr/dts/arm/st/f7/stm32f7.dtsi:861 */
			st,adc-clock-source = "SYNC";                                /* in zephyr/dts/arm/st/f7/stm32f7.dtsi:862 */
			st,adc-sequencer = "programmable";                           /* in zephyr/dts/arm/st/f7/stm32f7.dtsi:863 */
			st,adc-oversampler = "none";                                 /* in zephyr/dts/arm/st/f7/stm32f7.dtsi:864 */
			st,adc-internal-regulator = "none";                          /* in zephyr/dts/arm/st/f7/stm32f7.dtsi:865 */
			status = "disabled";                                         /* in zephyr/dts/arm/st/f7/stm32f7.dtsi:866 */
		};

		/* node '/soc/dac@40007400' defined in zephyr/dts/arm/st/f7/stm32f7.dtsi:869 */
		dac1: dac@40007400 {
			compatible = "st,stm32-dac";       /* in zephyr/dts/arm/st/f7/stm32f7.dtsi:870 */
			reg = < 0x40007400 0x400 >;        /* in zephyr/dts/arm/st/f7/stm32f7.dtsi:871 */
			clocks = < &rcc 0x40 0x20000000 >; /* in zephyr/dts/arm/st/f7/stm32f7.dtsi:872 */
			#io-channel-cells = < 0x1 >;       /* in zephyr/dts/arm/st/f7/stm32f7.dtsi:874 */
			status = "okay";                   /* in zephyr/boards/st/nucleo_f767zi/nucleo_f767zi.dts:184 */
			pinctrl-0 = < &dac_out1_pa4 >;     /* in zephyr/boards/st/nucleo_f767zi/nucleo_f767zi.dts:185 */
			pinctrl-names = "default";         /* in zephyr/boards/st/nucleo_f767zi/nucleo_f767zi.dts:186 */
		};

		/* node '/soc/dma@40026000' defined in zephyr/dts/arm/st/f7/stm32f7.dtsi:877 */
		dma1: dma@40026000 {
			compatible = "st,stm32-dma-v1";                                                      /* in zephyr/dts/arm/st/f7/stm32f7.dtsi:878 */
			#dma-cells = < 0x4 >;                                                                /* in zephyr/dts/arm/st/f7/stm32f7.dtsi:879 */
			reg = < 0x40026000 0x400 >;                                                          /* in zephyr/dts/arm/st/f7/stm32f7.dtsi:880 */
			interrupts = < 0xb 0x0 0xc 0x0 0xd 0x0 0xe 0x0 0xf 0x0 0x10 0x0 0x11 0x0 0x2f 0x0 >; /* in zephyr/dts/arm/st/f7/stm32f7.dtsi:881 */
			clocks = < &rcc 0x30 0x200000 >;                                                     /* in zephyr/dts/arm/st/f7/stm32f7.dtsi:882 */
			status = "disabled";                                                                 /* in zephyr/dts/arm/st/f7/stm32f7.dtsi:883 */
		};

		/* node '/soc/dma@40026400' defined in zephyr/dts/arm/st/f7/stm32f7.dtsi:886 */
		dma2: dma@40026400 {
			compatible = "st,stm32-dma-v1";                                                           /* in zephyr/dts/arm/st/f7/stm32f7.dtsi:887 */
			#dma-cells = < 0x4 >;                                                                     /* in zephyr/dts/arm/st/f7/stm32f7.dtsi:888 */
			reg = < 0x40026400 0x400 >;                                                               /* in zephyr/dts/arm/st/f7/stm32f7.dtsi:889 */
			interrupts = < 0x38 0x0 0x39 0x0 0x3a 0x0 0x3b 0x0 0x3c 0x0 0x44 0x0 0x45 0x0 0x46 0x0 >; /* in zephyr/dts/arm/st/f7/stm32f7.dtsi:890 */
			clocks = < &rcc 0x30 0x400000 >;                                                          /* in zephyr/dts/arm/st/f7/stm32f7.dtsi:891 */
			st,mem2mem;                                                                               /* in zephyr/dts/arm/st/f7/stm32f7.dtsi:892 */
			status = "disabled";                                                                      /* in zephyr/dts/arm/st/f7/stm32f7.dtsi:893 */
			phandle = < 0x2a >;                                                                       /* in zephyr/dts/arm/st/f7/stm32f7.dtsi:1000 */
		};

		/* node '/soc/rng@50060800' defined in zephyr/dts/arm/st/f7/stm32f7.dtsi:896 */
		rng: rng@50060800 {
			compatible = "st,stm32-rng";    /* in zephyr/dts/arm/st/f7/stm32f7.dtsi:897 */
			reg = < 0x50060800 0x400 >;     /* in zephyr/dts/arm/st/f7/stm32f7.dtsi:898 */
			interrupts = < 0x50 0x0 >;      /* in zephyr/dts/arm/st/f7/stm32f7.dtsi:899 */
			clocks = < &rcc 0x34 0x40 >,
			         < &rcc 0x7 0x1b0090 >; /* in zephyr/dts/arm/st/f7/stm32f7.dtsi:900 */
			status = "okay";                /* in zephyr/boards/st/nucleo_f767zi/nucleo_f767zi.dts:190 */
		};

		/* node '/soc/sdmmc@40012c00' defined in zephyr/dts/arm/st/f7/stm32f7.dtsi:905 */
		sdmmc1: sdmmc@40012c00 {
			compatible = "st,stm32-sdmmc";  /* in zephyr/dts/arm/st/f7/stm32f7.dtsi:906 */
			reg = < 0x40012c00 0x400 >;     /* in zephyr/dts/arm/st/f7/stm32f7.dtsi:907 */
			clocks = < &rcc 0x44 0x800 >,
			         < &rcc 0x7 0x1c0090 >; /* in zephyr/dts/arm/st/f7/stm32f7.dtsi:908 */
			resets = < &rctl 0x48b >;       /* in zephyr/dts/arm/st/f7/stm32f7.dtsi:910 */
			interrupts = < 0x31 0x0 >;      /* in zephyr/dts/arm/st/f7/stm32f7.dtsi:911 */
			status = "disabled";            /* in zephyr/dts/arm/st/f7/stm32f7.dtsi:912 */
		};

		/* node '/soc/memory@40024000' defined in zephyr/dts/arm/st/f7/stm32f7.dtsi:915 */
		backup_sram: memory@40024000 {
			compatible = "zephyr,memory-region",
			             "st,stm32-backup-sram";  /* in zephyr/dts/arm/st/f7/stm32f7.dtsi:916 */
			reg = < 0x40024000 0x1000 >;          /* in zephyr/dts/arm/st/f7/stm32f7.dtsi:917 */
			clocks = < &rcc 0x30 0x40000 >;       /* in zephyr/dts/arm/st/f7/stm32f7.dtsi:918 */
			zephyr,memory-region = "BACKUP_SRAM"; /* in zephyr/dts/arm/st/f7/stm32f7.dtsi:919 */
			status = "disabled";                  /* in zephyr/dts/arm/st/f7/stm32f7.dtsi:920 */
		};

		/* node '/soc/spi@a0001000' defined in zephyr/dts/arm/st/f7/stm32f7.dtsi:923 */
		quadspi: spi@a0001000 {
			compatible = "st,stm32-qspi";    /* in zephyr/dts/arm/st/f7/stm32f7.dtsi:924 */
			#address-cells = < 0x1 >;        /* in zephyr/dts/arm/st/f7/stm32f7.dtsi:925 */
			#size-cells = < 0x0 >;           /* in zephyr/dts/arm/st/f7/stm32f7.dtsi:926 */
			reg = < 0xa0001000 0x1000 >,
			      < 0x90000000 0x10000000 >; /* in zephyr/dts/arm/st/f7/stm32f7.dtsi:927 */
			interrupts = < 0x5c 0x0 >;       /* in zephyr/dts/arm/st/f7/stm32f7.dtsi:928 */
			clocks = < &rcc 0x38 0x2 >;      /* in zephyr/dts/arm/st/f7/stm32f7.dtsi:929 */
			status = "disabled";             /* in zephyr/dts/arm/st/f7/stm32f7.dtsi:930 */
		};

		/* node '/soc/i2c@40006000' defined in zephyr/dts/arm/st/f7/stm32f765.dtsi:49 */
		i2c4: i2c@40006000 {
			compatible = "st,stm32-i2c-v2";   /* in zephyr/dts/arm/st/f7/stm32f765.dtsi:50 */
			clock-frequency = < 0x186a0 >;    /* in zephyr/dts/arm/st/f7/stm32f765.dtsi:51 */
			#address-cells = < 0x1 >;         /* in zephyr/dts/arm/st/f7/stm32f765.dtsi:52 */
			#size-cells = < 0x0 >;            /* in zephyr/dts/arm/st/f7/stm32f765.dtsi:53 */
			reg = < 0x40006000 0x400 >;       /* in zephyr/dts/arm/st/f7/stm32f765.dtsi:54 */
			clocks = < &rcc 0x40 0x1000000 >; /* in zephyr/dts/arm/st/f7/stm32f765.dtsi:55 */
			interrupts = < 0x5f 0x0 >,
			             < 0x60 0x0 >;        /* in zephyr/dts/arm/st/f7/stm32f765.dtsi:56 */
			interrupt-names = "event",
			                  "error";        /* in zephyr/dts/arm/st/f7/stm32f765.dtsi:57 */
			status = "disabled";              /* in zephyr/dts/arm/st/f7/stm32f765.dtsi:58 */
			phandle = < 0x2b >;               /* in zephyr/dts/arm/st/f7/stm32f765.dtsi:111 */
		};

		/* node '/soc/spi@40015400' defined in zephyr/dts/arm/st/f7/stm32f765.dtsi:61 */
		spi6: spi@40015400 {
			compatible = "st,stm32-spi-fifo",
			             "st,stm32-spi";      /* in zephyr/dts/arm/st/f7/stm32f765.dtsi:62 */
			#address-cells = < 0x1 >;         /* in zephyr/dts/arm/st/f7/stm32f765.dtsi:63 */
			#size-cells = < 0x0 >;            /* in zephyr/dts/arm/st/f7/stm32f765.dtsi:64 */
			reg = < 0x40015400 0x400 >;       /* in zephyr/dts/arm/st/f7/stm32f765.dtsi:65 */
			clocks = < &rcc 0x44 0x200000 >;  /* in zephyr/dts/arm/st/f7/stm32f765.dtsi:66 */
			interrupts = < 0x56 0x5 >;        /* in zephyr/dts/arm/st/f7/stm32f765.dtsi:67 */
			status = "disabled";              /* in zephyr/dts/arm/st/f7/stm32f765.dtsi:68 */
		};

		/* node '/soc/ethernet@40028000' defined in zephyr/dts/arm/st/f7/stm32f765.dtsi:71 */
		ethernet@40028000 {
			reg = < 0x40028000 0x8000 >;                 /* in zephyr/dts/arm/st/f7/stm32f765.dtsi:72 */
			compatible = "st,stm32-ethernet-controller"; /* in zephyr/dts/arm/st/f7/stm32f765.dtsi:73 */
			clock-names = "stm-eth";                     /* in zephyr/dts/arm/st/f7/stm32f765.dtsi:74 */
			clocks = < &rcc 0x30 0x2000000 >;            /* in zephyr/dts/arm/st/f7/stm32f765.dtsi:75 */

			/* node '/soc/ethernet@40028000/ethernet' defined in zephyr/dts/arm/st/f7/stm32f765.dtsi:77 */
			mac: ethernet {
				compatible = "st,stm32-ethernet";                                                                         /* in zephyr/dts/arm/st/f7/stm32f765.dtsi:78 */
				interrupts = < 0x3d 0x0 >;                                                                                /* in zephyr/dts/arm/st/f7/stm32f765.dtsi:79 */
				clock-names = "mac-clk-tx",
				              "mac-clk-rx",
				              "mac-clk-ptp";                                                                              /* in zephyr/dts/arm/st/f7/stm32f765.dtsi:80 */
				clocks = < &rcc 0x30 0x4000000 >,
				         < &rcc 0x30 0x8000000 >,
				         < &rcc 0x30 0x10000000 >;                                                                        /* in zephyr/dts/arm/st/f7/stm32f765.dtsi:82 */
				status = "okay";                                                                                          /* in zephyr/boards/st/nucleo_f767zi/nucleo_f767zi.dts:194 */
				pinctrl-0 = < &eth_rxd0_pc4 &eth_rxd1_pc5 &eth_ref_clk_pa1 &eth_crs_dv_pa7 &eth_tx_en_pg11 &eth_txd0_pg13
				              &eth_txd1_pb13 >;                                                                           /* in zephyr/boards/st/nucleo_f767zi/nucleo_f767zi.dts:195 */
				pinctrl-names = "default";                                                                                /* in zephyr/boards/st/nucleo_f767zi/nucleo_f767zi.dts:202 */
				phy-connection-type = "rmii";                                                                             /* in zephyr/boards/st/nucleo_f767zi/nucleo_f767zi.dts:203 */
				phy-handle = < &eth_phy >;                                                                                /* in zephyr/boards/st/nucleo_f767zi/nucleo_f767zi.dts:204 */
			};

			/* node '/soc/ethernet@40028000/mdio' defined in zephyr/dts/arm/st/f7/stm32f765.dtsi:88 */
			mdio: mdio {
				compatible = "st,stm32-mdio";               /* in zephyr/dts/arm/st/f7/stm32f765.dtsi:89 */
				#address-cells = < 0x1 >;                   /* in zephyr/dts/arm/st/f7/stm32f765.dtsi:90 */
				#size-cells = < 0x0 >;                      /* in zephyr/dts/arm/st/f7/stm32f765.dtsi:91 */
				status = "okay";                            /* in zephyr/boards/st/nucleo_f767zi/nucleo_f767zi.dts:208 */
				pinctrl-0 = < &eth_mdio_pa2 &eth_mdc_pc1 >; /* in zephyr/boards/st/nucleo_f767zi/nucleo_f767zi.dts:209 */
				pinctrl-names = "default";                  /* in zephyr/boards/st/nucleo_f767zi/nucleo_f767zi.dts:210 */

				/* node '/soc/ethernet@40028000/mdio/ethernet-phy@0' defined in zephyr/boards/st/nucleo_f767zi/nucleo_f767zi.dts:212 */
				eth_phy: ethernet-phy@0 {
					compatible = "ethernet-phy"; /* in zephyr/boards/st/nucleo_f767zi/nucleo_f767zi.dts:213 */
					reg = < 0x0 >;               /* in zephyr/boards/st/nucleo_f767zi/nucleo_f767zi.dts:214 */
					phandle = < 0x23 >;          /* in zephyr/boards/st/nucleo_f767zi/nucleo_f767zi.dts:204 */
				};
			};
		};

		/* node '/soc/sdmmc@40011c00' defined in zephyr/dts/arm/st/f7/stm32f765.dtsi:96 */
		sdmmc2: sdmmc@40011c00 {
			compatible = "st,stm32-sdmmc";  /* in zephyr/dts/arm/st/f7/stm32f765.dtsi:97 */
			reg = < 0x40011c00 0x400 >;     /* in zephyr/dts/arm/st/f7/stm32f765.dtsi:98 */
			clocks = < &rcc 0x44 0x80 >,
			         < &rcc 0x7 0x1d0090 >; /* in zephyr/dts/arm/st/f7/stm32f765.dtsi:99 */
			resets = < &rctl 0x487 >;       /* in zephyr/dts/arm/st/f7/stm32f765.dtsi:101 */
			interrupts = < 0x67 0x0 >;      /* in zephyr/dts/arm/st/f7/stm32f765.dtsi:102 */
			status = "disabled";            /* in zephyr/dts/arm/st/f7/stm32f765.dtsi:103 */
		};

		/* node '/soc/display-controller@40016800' defined in zephyr/dts/arm/st/f7/stm32f767.dtsi:15 */
		ltdc: display-controller@40016800 {
			compatible = "st,stm32-ltdc";     /* in zephyr/dts/arm/st/f7/stm32f767.dtsi:16 */
			reg = < 0x40016800 0x200 >;       /* in zephyr/dts/arm/st/f7/stm32f767.dtsi:17 */
			interrupts = < 0x58 0x0 >,
			             < 0x59 0x0 >;        /* in zephyr/dts/arm/st/f7/stm32f767.dtsi:18 */
			interrupt-names = "ltdc",
			                  "ltdc_err";     /* in zephyr/dts/arm/st/f7/stm32f767.dtsi:19 */
			clocks = < &rcc 0x44 0x4000000 >; /* in zephyr/dts/arm/st/f7/stm32f767.dtsi:20 */
			resets = < &rctl 0x49a >;         /* in zephyr/dts/arm/st/f7/stm32f767.dtsi:21 */
			status = "disabled";              /* in zephyr/dts/arm/st/f7/stm32f767.dtsi:22 */
		};

		/* node '/soc/dsihost@40016c00' defined in zephyr/dts/arm/st/f7/stm32f767.dtsi:25 */
		mipi_dsi: dsihost@40016c00 {
			compatible = "st,stm32-mipi-dsi"; /* in zephyr/dts/arm/st/f7/stm32f767.dtsi:26 */
			#address-cells = < 0x1 >;         /* in zephyr/dts/arm/st/f7/stm32f767.dtsi:27 */
			#size-cells = < 0x0 >;            /* in zephyr/dts/arm/st/f7/stm32f767.dtsi:28 */
			reg = < 0x40016c00 0x800 >;       /* in zephyr/dts/arm/st/f7/stm32f767.dtsi:29 */
			clock-names = "dsiclk",
			              "refclk",
			              "pixelclk";         /* in zephyr/dts/arm/st/f7/stm32f767.dtsi:30 */
			clocks = < &rcc 0x44 0x8000000 >,
			         < &rcc 0x5 0xff >,
			         < &rcc 0x11 0xff >;      /* in zephyr/dts/arm/st/f7/stm32f767.dtsi:31 */
			resets = < &rctl 0x49b >;         /* in zephyr/dts/arm/st/f7/stm32f767.dtsi:34 */
			status = "disabled";              /* in zephyr/dts/arm/st/f7/stm32f767.dtsi:35 */
		};
	};

	/* node '/cpus' defined in zephyr/dts/arm/st/f7/stm32f7.dtsi:33 */
	cpus {
		#address-cells = < 0x1 >; /* in zephyr/dts/arm/st/f7/stm32f7.dtsi:34 */
		#size-cells = < 0x0 >;    /* in zephyr/dts/arm/st/f7/stm32f7.dtsi:35 */

		/* node '/cpus/cpu@0' defined in zephyr/dts/arm/st/f7/stm32f7.dtsi:37 */
		cpu0: cpu@0 {
			device_type = "cpu";          /* in zephyr/dts/arm/st/f7/stm32f7.dtsi:38 */
			compatible = "arm,cortex-m7"; /* in zephyr/dts/arm/st/f7/stm32f7.dtsi:39 */
			reg = < 0x0 >;                /* in zephyr/dts/arm/st/f7/stm32f7.dtsi:40 */
			#address-cells = < 0x1 >;     /* in zephyr/dts/arm/st/f7/stm32f7.dtsi:41 */
			#size-cells = < 0x1 >;        /* in zephyr/dts/arm/st/f7/stm32f7.dtsi:42 */

			/* node '/cpus/cpu@0/mpu@e000ed90' defined in zephyr/dts/arm/st/f7/stm32f7.dtsi:44 */
			mpu: mpu@e000ed90 {
				compatible = "arm,armv7m-mpu"; /* in zephyr/dts/arm/st/f7/stm32f7.dtsi:45 */
				reg = < 0xe000ed90 0x40 >;     /* in zephyr/dts/arm/st/f7/stm32f7.dtsi:46 */
			};
		};
	};

	/* node '/memory-placeholder@90000000' defined in zephyr/dts/arm/st/f7/stm32f7.dtsi:51 */
	quadspi_memory: memory-placeholder@90000000 {
		compatible = "zephyr,memory-region",
		             "mmio-sram";                  /* in zephyr/dts/arm/st/f7/stm32f7.dtsi:52 */
		reg = < 0x90000000 0x10000000 >;           /* in zephyr/dts/arm/st/f7/stm32f7.dtsi:53 */
		zephyr,memory-region = "QSPI_PLACEHOLDER"; /* in zephyr/dts/arm/st/f7/stm32f7.dtsi:54 */
		zephyr,memory-attr = < 0x2000000 >;        /* in zephyr/dts/arm/st/f7/stm32f7.dtsi:55 */
	};

	/* node '/clocks' defined in zephyr/dts/arm/st/f7/stm32f7.dtsi:58 */
	clocks {

		/* node '/clocks/clk-hse' defined in zephyr/dts/arm/st/f7/stm32f7.dtsi:59 */
		clk_hse: clk-hse {
			#clock-cells = < 0x0 >;            /* in zephyr/dts/arm/st/f7/stm32f7.dtsi:60 */
			compatible = "st,stm32-hse-clock"; /* in zephyr/dts/arm/st/f7/stm32f7.dtsi:61 */
			hse-bypass;                        /* in zephyr/boards/st/nucleo_f767zi/nucleo_f767zi.dts:79 */
			clock-frequency = < 0x7a1200 >;    /* in zephyr/boards/st/nucleo_f767zi/nucleo_f767zi.dts:80 */
			status = "okay";                   /* in zephyr/boards/st/nucleo_f767zi/nucleo_f767zi.dts:81 */
			phandle = < 0x26 >;                /* in zephyr/boards/st/nucleo_f767zi/nucleo_f767zi.dts:89 */
		};

		/* node '/clocks/clk-hsi' defined in zephyr/dts/arm/st/f7/stm32f7.dtsi:65 */
		clk_hsi: clk-hsi {
			#clock-cells = < 0x0 >;         /* in zephyr/dts/arm/st/f7/stm32f7.dtsi:66 */
			compatible = "fixed-clock";     /* in zephyr/dts/arm/st/f7/stm32f7.dtsi:67 */
			clock-frequency = < 0xf42400 >; /* in zephyr/dts/arm/st/f7/stm32f7.dtsi:68 */
			status = "disabled";            /* in zephyr/dts/arm/st/f7/stm32f7.dtsi:69 */
		};

		/* node '/clocks/clk-lse' defined in zephyr/dts/arm/st/f7/stm32f7.dtsi:72 */
		clk_lse: clk-lse {
			#clock-cells = < 0x0 >;            /* in zephyr/dts/arm/st/f7/stm32f7.dtsi:73 */
			compatible = "st,stm32-lse-clock"; /* in zephyr/dts/arm/st/f7/stm32f7.dtsi:74 */
			clock-frequency = < 0x8000 >;      /* in zephyr/dts/arm/st/f7/stm32f7.dtsi:75 */
			driving-capability = < 0x0 >;      /* in zephyr/dts/arm/st/f7/stm32f7.dtsi:76 */
			status = "disabled";               /* in zephyr/dts/arm/st/f7/stm32f7.dtsi:77 */
		};

		/* node '/clocks/clk-lsi' defined in zephyr/dts/arm/st/f7/stm32f7.dtsi:80 */
		clk_lsi: clk-lsi {
			#clock-cells = < 0x0 >;       /* in zephyr/dts/arm/st/f7/stm32f7.dtsi:81 */
			compatible = "fixed-clock";   /* in zephyr/dts/arm/st/f7/stm32f7.dtsi:82 */
			clock-frequency = < 0x7d00 >; /* in zephyr/dts/arm/st/f7/stm32f7.dtsi:83 */
			status = "okay";              /* in zephyr/boards/st/nucleo_f767zi/nucleo_f767zi.dts:75 */
		};

		/* node '/clocks/pll' defined in zephyr/dts/arm/st/f7/stm32f7.dtsi:87 */
		pll: pll {
			#clock-cells = < 0x0 >;              /* in zephyr/dts/arm/st/f7/stm32f7.dtsi:88 */
			compatible = "st,stm32f7-pll-clock"; /* in zephyr/dts/arm/st/f7/stm32f7.dtsi:89 */
			div-m = < 0x4 >;                     /* in zephyr/boards/st/nucleo_f767zi/nucleo_f767zi.dts:85 */
			mul-n = < 0xd8 >;                    /* in zephyr/boards/st/nucleo_f767zi/nucleo_f767zi.dts:86 */
			div-p = < 0x2 >;                     /* in zephyr/boards/st/nucleo_f767zi/nucleo_f767zi.dts:87 */
			div-q = < 0x9 >;                     /* in zephyr/boards/st/nucleo_f767zi/nucleo_f767zi.dts:88 */
			clocks = < &clk_hse >;               /* in zephyr/boards/st/nucleo_f767zi/nucleo_f767zi.dts:89 */
			status = "okay";                     /* in zephyr/boards/st/nucleo_f767zi/nucleo_f767zi.dts:90 */
			phandle = < 0x3 >;                   /* in zephyr/boards/st/nucleo_f767zi/nucleo_f767zi.dts:94 */
		};

		/* node '/clocks/pllsai' defined in zephyr/dts/arm/st/f7/stm32f7.dtsi:93 */
		pllsai: pllsai {
			compatible = "st,stm32fx-pllsai-clock"; /* in zephyr/dts/arm/st/f7/stm32f7.dtsi:94 */
			#clock-cells = < 0x0 >;                 /* in zephyr/dts/arm/st/f7/stm32f7.dtsi:95 */
			status = "disabled";                    /* in zephyr/dts/arm/st/f7/stm32f7.dtsi:96 */
		};
	};

	/* node '/mcos' defined in zephyr/dts/arm/st/f7/stm32f7.dtsi:100 */
	mcos {

		/* node '/mcos/mco1' defined in zephyr/dts/arm/st/f7/stm32f7.dtsi:101 */
		mco1: mco1 {
			compatible = "st,stm32-clock-mco"; /* in zephyr/dts/arm/st/f7/stm32f7.dtsi:102 */
			status = "disabled";               /* in zephyr/dts/arm/st/f7/stm32f7.dtsi:103 */
		};

		/* node '/mcos/mco2' defined in zephyr/dts/arm/st/f7/stm32f7.dtsi:106 */
		mco2: mco2 {
			compatible = "st,stm32-clock-mco"; /* in zephyr/dts/arm/st/f7/stm32f7.dtsi:107 */
			status = "disabled";               /* in zephyr/dts/arm/st/f7/stm32f7.dtsi:108 */
		};
	};

	/* node '/dietemp' defined in zephyr/dts/arm/st/f7/stm32f7.dtsi:934 */
	die_temp: dietemp {
		compatible = "st,stm32-temp-cal"; /* in zephyr/dts/arm/st/f7/stm32f7.dtsi:935 */
		ts-cal1-addr = < 0x1ff0f44c >;    /* in zephyr/dts/arm/st/f7/stm32f7.dtsi:936 */
		ts-cal2-addr = < 0x1ff0f44e >;    /* in zephyr/dts/arm/st/f7/stm32f7.dtsi:937 */
		ts-cal1-temp = < 0x1e >;          /* in zephyr/dts/arm/st/f7/stm32f7.dtsi:938 */
		ts-cal2-temp = < 0x6e >;          /* in zephyr/dts/arm/st/f7/stm32f7.dtsi:939 */
		ts-cal-vrefanalog = < 0xce4 >;    /* in zephyr/dts/arm/st/f7/stm32f7.dtsi:940 */
		io-channels = < &adc1 0x12 >;     /* in zephyr/dts/arm/st/f7/stm32f7.dtsi:941 */
		status = "disabled";              /* in zephyr/dts/arm/st/f7/stm32f7.dtsi:942 */
	};

	/* node '/vref' defined in zephyr/dts/arm/st/f7/stm32f7.dtsi:945 */
	vref: vref {
		compatible = "st,stm32-vref";      /* in zephyr/dts/arm/st/f7/stm32f7.dtsi:946 */
		vrefint-cal-addr = < 0x1ff0f44a >; /* in zephyr/dts/arm/st/f7/stm32f7.dtsi:947 */
		vrefint-cal-mv = < 0xce4 >;        /* in zephyr/dts/arm/st/f7/stm32f7.dtsi:948 */
		io-channels = < &adc1 0x11 >;      /* in zephyr/dts/arm/st/f7/stm32f7.dtsi:949 */
		status = "okay";                   /* in zephyr/boards/st/nucleo_f767zi/nucleo_f767zi.dts:275 */
	};

	/* node '/vbat' defined in zephyr/dts/arm/st/f7/stm32f7.dtsi:953 */
	vbat: vbat {
		compatible = "st,stm32-vbat"; /* in zephyr/dts/arm/st/f7/stm32f7.dtsi:954 */
		ratio = < 0x4 >;              /* in zephyr/dts/arm/st/f7/stm32f7.dtsi:955 */
		io-channels = < &adc1 0x12 >; /* in zephyr/dts/arm/st/f7/stm32f7.dtsi:956 */
		status = "okay";              /* in zephyr/boards/st/nucleo_f767zi/nucleo_f767zi.dts:279 */
	};

	/* node '/otghs_fs_phy' defined in zephyr/dts/arm/st/f7/stm32f7.dtsi:960 */
	otghs_fs_phy: otghs_fs_phy {
		compatible = "usb-nop-xceiv"; /* in zephyr/dts/arm/st/f7/stm32f7.dtsi:961 */
		#phy-cells = < 0x0 >;         /* in zephyr/dts/arm/st/f7/stm32f7.dtsi:962 */
		phandle = < 0x19 >;           /* in zephyr/dts/arm/st/f7/stm32f7.dtsi:791 */
	};

	/* node '/otgfs_phy' defined in zephyr/dts/arm/st/f7/stm32f7.dtsi:965 */
	otgfs_phy: otgfs_phy {
		compatible = "usb-nop-xceiv"; /* in zephyr/dts/arm/st/f7/stm32f7.dtsi:966 */
		#phy-cells = < 0x0 >;         /* in zephyr/dts/arm/st/f7/stm32f7.dtsi:967 */
		phandle = < 0x16 >;           /* in zephyr/dts/arm/st/f7/stm32f7.dtsi:775 */
	};

	/* node '/smbus1' defined in zephyr/dts/arm/st/f7/stm32f7.dtsi:970 */
	smbus1: smbus1 {
		compatible = "st,stm32-smbus"; /* in zephyr/dts/arm/st/f7/stm32f7.dtsi:971 */
		#address-cells = < 0x1 >;      /* in zephyr/dts/arm/st/f7/stm32f7.dtsi:972 */
		#size-cells = < 0x0 >;         /* in zephyr/dts/arm/st/f7/stm32f7.dtsi:973 */
		i2c = < &i2c2 >;               /* in zephyr/dts/arm/st/f7/stm32f7.dtsi:974 */
		status = "disabled";           /* in zephyr/dts/arm/st/f7/stm32f7.dtsi:975 */
	};

	/* node '/smbus2' defined in zephyr/dts/arm/st/f7/stm32f7.dtsi:978 */
	smbus2: smbus2 {
		compatible = "st,stm32-smbus"; /* in zephyr/dts/arm/st/f7/stm32f7.dtsi:979 */
		#address-cells = < 0x1 >;      /* in zephyr/dts/arm/st/f7/stm32f7.dtsi:980 */
		#size-cells = < 0x0 >;         /* in zephyr/dts/arm/st/f7/stm32f7.dtsi:981 */
		i2c = < &i2c2 >;               /* in zephyr/dts/arm/st/f7/stm32f7.dtsi:982 */
		status = "disabled";           /* in zephyr/dts/arm/st/f7/stm32f7.dtsi:983 */
	};

	/* node '/smbus3' defined in zephyr/dts/arm/st/f7/stm32f7.dtsi:986 */
	smbus3: smbus3 {
		compatible = "st,stm32-smbus"; /* in zephyr/dts/arm/st/f7/stm32f7.dtsi:987 */
		#address-cells = < 0x1 >;      /* in zephyr/dts/arm/st/f7/stm32f7.dtsi:988 */
		#size-cells = < 0x0 >;         /* in zephyr/dts/arm/st/f7/stm32f7.dtsi:989 */
		i2c = < &i2c3 >;               /* in zephyr/dts/arm/st/f7/stm32f7.dtsi:990 */
		status = "disabled";           /* in zephyr/dts/arm/st/f7/stm32f7.dtsi:991 */
	};

	/* node '/sai1@40015804' defined in zephyr/dts/arm/st/f7/stm32f7.dtsi:994 */
	sai1_a: sai1@40015804 {
		compatible = "st,stm32-sai";          /* in zephyr/dts/arm/st/f7/stm32f7.dtsi:995 */
		#address-cells = < 0x1 >;             /* in zephyr/dts/arm/st/f7/stm32f7.dtsi:996 */
		#size-cells = < 0x0 >;                /* in zephyr/dts/arm/st/f7/stm32f7.dtsi:997 */
		reg = < 0x40015804 0x20 >;            /* in zephyr/dts/arm/st/f7/stm32f7.dtsi:998 */
		clocks = < &rcc 0x44 0x400000 >;      /* in zephyr/dts/arm/st/f7/stm32f7.dtsi:999 */
		dmas = < &dma2 0x1 0x0 0x22800 0x0 >; /* in zephyr/dts/arm/st/f7/stm32f7.dtsi:1000 */
		status = "disabled";                  /* in zephyr/dts/arm/st/f7/stm32f7.dtsi:1002 */
	};

	/* node '/sai1@40015824' defined in zephyr/dts/arm/st/f7/stm32f7.dtsi:1005 */
	sai1_b: sai1@40015824 {
		compatible = "st,stm32-sai";          /* in zephyr/dts/arm/st/f7/stm32f7.dtsi:1006 */
		#address-cells = < 0x1 >;             /* in zephyr/dts/arm/st/f7/stm32f7.dtsi:1007 */
		#size-cells = < 0x0 >;                /* in zephyr/dts/arm/st/f7/stm32f7.dtsi:1008 */
		reg = < 0x40015824 0x20 >;            /* in zephyr/dts/arm/st/f7/stm32f7.dtsi:1009 */
		clocks = < &rcc 0x44 0x400000 >;      /* in zephyr/dts/arm/st/f7/stm32f7.dtsi:1010 */
		dmas = < &dma2 0x5 0x0 0x22800 0x0 >; /* in zephyr/dts/arm/st/f7/stm32f7.dtsi:1011 */
		status = "disabled";                  /* in zephyr/dts/arm/st/f7/stm32f7.dtsi:1013 */
	};

	/* node '/memory@20020000' defined in zephyr/dts/arm/st/f7/stm32f765.dtsi:14 */
	sram0: memory@20020000 {
		compatible = "zephyr,memory-region",
		             "mmio-sram";            /* in zephyr/dts/arm/st/f7/stm32f765.dtsi:15 */
		reg = < 0x20020000 0x60000 >;        /* in zephyr/dts/arm/st/f7/stm32f765.dtsi:16 */
		zephyr,memory-region = "SRAM0";      /* in zephyr/dts/arm/st/f7/stm32f765.dtsi:17 */
	};

	/* node '/memory@20000000' defined in zephyr/dts/arm/st/f7/stm32f765.dtsi:20 */
	dtcm: memory@20000000 {
		compatible = "zephyr,memory-region",
		             "arm,dtcm";             /* in zephyr/dts/arm/st/f7/stm32f765.dtsi:21 */
		reg = < 0x20000000 0x20000 >;        /* in zephyr/dts/arm/st/f7/stm32f765.dtsi:22 */
		zephyr,memory-region = "DTCM";       /* in zephyr/dts/arm/st/f7/stm32f765.dtsi:23 */
	};

	/* node '/smbus4' defined in zephyr/dts/arm/st/f7/stm32f765.dtsi:107 */
	smbus4: smbus4 {
		compatible = "st,stm32-smbus"; /* in zephyr/dts/arm/st/f7/stm32f765.dtsi:108 */
		#address-cells = < 0x1 >;      /* in zephyr/dts/arm/st/f7/stm32f765.dtsi:109 */
		#size-cells = < 0x0 >;         /* in zephyr/dts/arm/st/f7/stm32f765.dtsi:110 */
		i2c = < &i2c4 >;               /* in zephyr/dts/arm/st/f7/stm32f765.dtsi:111 */
		status = "disabled";           /* in zephyr/dts/arm/st/f7/stm32f765.dtsi:112 */
	};

	/* node '/connector' defined in zephyr/boards/st/nucleo_f767zi/arduino_r3_connector.dtsi:10 */
	arduino_header: connector {
		compatible = "arduino-header-r3";          /* in zephyr/boards/st/nucleo_f767zi/arduino_r3_connector.dtsi:11 */
		#gpio-cells = < 0x2 >;                     /* in zephyr/boards/st/nucleo_f767zi/arduino_r3_connector.dtsi:12 */
		gpio-map-mask = < 0xffffffff 0xffffffc0 >; /* in zephyr/boards/st/nucleo_f767zi/arduino_r3_connector.dtsi:13 */
		gpio-map-pass-thru = < 0x0 0x3f >;         /* in zephyr/boards/st/nucleo_f767zi/arduino_r3_connector.dtsi:14 */
		gpio-map = < 0x0 0x0 &gpioa 0x3 0x0 >,
		           < 0x1 0x0 &gpioc 0x0 0x0 >,
		           < 0x2 0x0 &gpioc 0x3 0x0 >,
		           < 0x3 0x0 &gpiof 0x3 0x0 >,
		           < 0x4 0x0 &gpiof 0x5 0x0 >,
		           < 0x5 0x0 &gpiof 0xa 0x0 >,
		           < 0x6 0x0 &gpiog 0x9 0x0 >,
		           < 0x7 0x0 &gpiog 0xe 0x0 >,
		           < 0x8 0x0 &gpiof 0xf 0x0 >,
		           < 0x9 0x0 &gpioe 0xd 0x0 >,
		           < 0xa 0x0 &gpiof 0xe 0x0 >,
		           < 0xb 0x0 &gpioe 0xb 0x0 >,
		           < 0xc 0x0 &gpioe 0x9 0x0 >,
		           < 0xd 0x0 &gpiof 0xd 0x0 >,
		           < 0xe 0x0 &gpiof 0xc 0x0 >,
		           < 0xf 0x0 &gpiod 0xf 0x0 >,
		           < 0x10 0x0 &gpiod 0xe 0x0 >,
		           < 0x11 0x0 &gpioa 0x7 0x0 >,
		           < 0x12 0x0 &gpioa 0x6 0x0 >,
		           < 0x13 0x0 &gpioa 0x5 0x0 >,
		           < 0x14 0x0 &gpiob 0x9 0x0 >,
		           < 0x15 0x0 &gpiob 0x8 0x0 >;    /* in zephyr/boards/st/nucleo_f767zi/arduino_r3_connector.dtsi:15 */
	};

	/* node '/leds' defined in zephyr/boards/st/nucleo_f767zi/nucleo_f767zi.dts:34 */
	leds: leds {
		compatible = "gpio-leds"; /* in zephyr/boards/st/nucleo_f767zi/nucleo_f767zi.dts:35 */

		/* node '/leds/led_0' defined in zephyr/boards/st/nucleo_f767zi/nucleo_f767zi.dts:37 */
		green_led: led_0 {
			gpios = < &gpiob 0x0 0x0 >; /* in zephyr/boards/st/nucleo_f767zi/nucleo_f767zi.dts:38 */
			label = "User LD1";         /* in zephyr/boards/st/nucleo_f767zi/nucleo_f767zi.dts:39 */
		};

		/* node '/leds/led_1' defined in zephyr/boards/st/nucleo_f767zi/nucleo_f767zi.dts:42 */
		blue_led: led_1 {
			gpios = < &gpiob 0x7 0x0 >; /* in zephyr/boards/st/nucleo_f767zi/nucleo_f767zi.dts:43 */
			label = "User LD2";         /* in zephyr/boards/st/nucleo_f767zi/nucleo_f767zi.dts:44 */
		};

		/* node '/leds/led_2' defined in zephyr/boards/st/nucleo_f767zi/nucleo_f767zi.dts:47 */
		red_led: led_2 {
			gpios = < &gpiob 0xe 0x0 >; /* in zephyr/boards/st/nucleo_f767zi/nucleo_f767zi.dts:48 */
			label = "User LD3";         /* in zephyr/boards/st/nucleo_f767zi/nucleo_f767zi.dts:49 */
		};
	};

	/* node '/gpio_keys' defined in zephyr/boards/st/nucleo_f767zi/nucleo_f767zi.dts:53 */
	gpio_keys {
		compatible = "gpio-keys"; /* in zephyr/boards/st/nucleo_f767zi/nucleo_f767zi.dts:54 */

		/* node '/gpio_keys/button_0' defined in zephyr/boards/st/nucleo_f767zi/nucleo_f767zi.dts:56 */
		user_button: button_0 {
			label = "User";             /* in zephyr/boards/st/nucleo_f767zi/nucleo_f767zi.dts:57 */
			gpios = < &gpioc 0xd 0x1 >; /* in zephyr/boards/st/nucleo_f767zi/nucleo_f767zi.dts:58 */
			zephyr,code = < 0xb >;      /* in zephyr/boards/st/nucleo_f767zi/nucleo_f767zi.dts:59 */
		};
	};
};
